AUTOSAR XML (schema 4-0-3)
package /CSCR_Code_pkg/CSCR_Code_swc
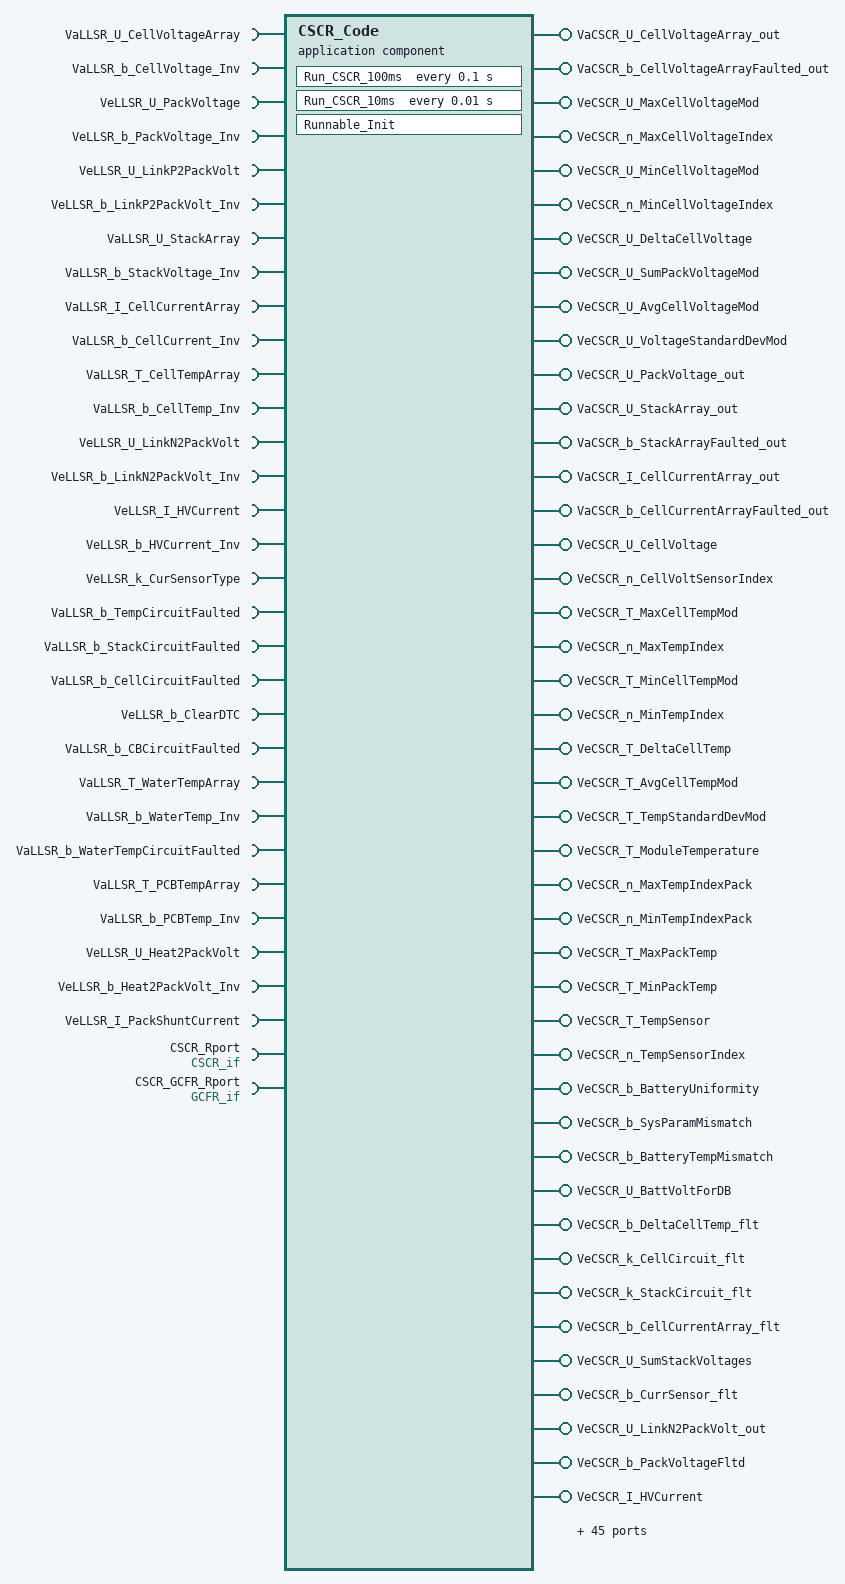
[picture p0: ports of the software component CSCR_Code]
  application sw component type CSCR_Code
    30 x require port:
      VaLLSR_U_CellVoltageArray: nonqueued-receiver-com-spec{data-element=VaLLSR_U_CellVoltageArray, init-value=96 x 0}, required-interface=VaLLSR_U_CellVoltageArray
      VaLLSR_b_CellVoltage_Inv: nonqueued-receiver-com-spec{data-element=VaLLSR_b_CellVoltage_Inv, init-value=96 x 0}, required-interface=VaLLSR_b_CellVoltage_Inv
      VeLLSR_U_PackVoltage: nonqueued-receiver-com-spec{data-element=VeLLSR_U_PackVoltage, init-value=0}, required-interface=VeLLSR_U_PackVoltage
      VeLLSR_b_PackVoltage_Inv: nonqueued-receiver-com-spec{data-element=VeLLSR_b_PackVoltage_Inv, init-value=0}, required-interface=VeLLSR_b_PackVoltage_Inv
      VeLLSR_U_LinkP2PackVolt: nonqueued-receiver-com-spec{data-element=VeLLSR_U_LinkP2PackVolt, init-value=0}, required-interface=VeLLSR_U_LinkP2PackVolt
      VeLLSR_b_LinkP2PackVolt_Inv: nonqueued-receiver-com-spec{data-element=VeLLSR_b_LinkP2PackVolt_Inv, init-value=0}, required-interface=VeLLSR_b_LinkP2PackVolt_Inv
      VaLLSR_U_StackArray: nonqueued-receiver-com-spec{data-element=VaLLSR_U_StackArray, init-value=8 x 0}, required-interface=VaLLSR_U_StackArray
      VaLLSR_b_StackVoltage_Inv: nonqueued-receiver-com-spec{data-element=VaLLSR_b_StackVoltage_Inv, init-value=8 x 0}, required-interface=VaLLSR_b_StackVoltage_Inv
      VaLLSR_I_CellCurrentArray: nonqueued-receiver-com-spec{data-element=VaLLSR_I_CellCurrentArray, init-value=[0, 0]}, required-interface=VaLLSR_I_CellCurrentArray
      VaLLSR_b_CellCurrent_Inv: nonqueued-receiver-com-spec{data-element=VaLLSR_b_CellCurrent_Inv, init-value=[0, 0]}, required-interface=VaLLSR_b_CellCurrent_Inv
      VaLLSR_T_CellTempArray: nonqueued-receiver-com-spec{data-element=VaLLSR_T_CellTempArray, init-value=16 x 0}, required-interface=VaLLSR_T_CellTempArray
      VaLLSR_b_CellTemp_Inv: nonqueued-receiver-com-spec{data-element=VaLLSR_b_CellTemp_Inv, init-value=16 x 0}, required-interface=VaLLSR_b_CellTemp_Inv
      VeLLSR_U_LinkN2PackVolt: nonqueued-receiver-com-spec{data-element=VeLLSR_U_LinkN2PackVolt, init-value=0}, required-interface=VeLLSR_U_LinkN2PackVolt
      VeLLSR_b_LinkN2PackVolt_Inv: nonqueued-receiver-com-spec{data-element=VeLLSR_b_LinkN2PackVolt_Inv, init-value=0}, required-interface=VeLLSR_b_LinkN2PackVolt_Inv
      VeLLSR_I_HVCurrent: nonqueued-receiver-com-spec{data-element=VeLLSR_I_HVCurrent, init-value=0}, required-interface=VeLLSR_I_HVCurrent
      VeLLSR_b_HVCurrent_Inv: nonqueued-receiver-com-spec{data-element=VeLLSR_b_HVCurrent_Inv, init-value=0}, required-interface=VeLLSR_b_HVCurrent_Inv
      VeLLSR_k_CurSensorType: nonqueued-receiver-com-spec{data-element=VeLLSR_k_CurSensorType, init-value=0}, required-interface=VeLLSR_k_CurSensorType
      VaLLSR_b_TempCircuitFaulted: nonqueued-receiver-com-spec{data-element=VaLLSR_b_TempCircuitFaulted, init-value=16 x 0}, required-interface=VaLLSR_b_TempCircuitFaulted
      VaLLSR_b_StackCircuitFaulted: nonqueued-receiver-com-spec{data-element=VaLLSR_b_StackCircuitFaulted, init-value=8 x 0}, required-interface=VaLLSR_b_StackCircuitFaulted
      VaLLSR_b_CellCircuitFaulted: nonqueued-receiver-com-spec{data-element=VaLLSR_b_CellCircuitFaulted, init-value=96 x 0}, required-interface=VaLLSR_b_CellCircuitFaulted
      VeLLSR_b_ClearDTC: nonqueued-receiver-com-spec{data-element=VeLLSR_b_ClearDTC, init-value=0}, required-interface=VeLLSR_b_ClearDTC
      VaLLSR_b_CBCircuitFaulted: nonqueued-receiver-com-spec{data-element=VaLLSR_b_CBCircuitFaulted, init-value=96 x 0}, required-interface=VaLLSR_b_CBCircuitFaulted
      VaLLSR_T_WaterTempArray: nonqueued-receiver-com-spec{data-element=VaLLSR_T_WaterTempArray, init-value=[0, 0]}, required-interface=VaLLSR_T_WaterTempArray
      VaLLSR_b_WaterTemp_Inv: nonqueued-receiver-com-spec{data-element=VaLLSR_b_WaterTemp_Inv, init-value=[0, 0]}, required-interface=VaLLSR_b_WaterTemp_Inv
      VaLLSR_b_WaterTempCircuitFaulted: nonqueued-receiver-com-spec{data-element=VaLLSR_b_WaterTempCircuitFaulted, init-value=[0, 0]}, required-interface=VaLLSR_b_WaterTempCircuitFaulted
      VaLLSR_T_PCBTempArray: nonqueued-receiver-com-spec{data-element=VaLLSR_T_PCBTempArray, init-value=11 x 0}, required-interface=VaLLSR_T_PCBTempArray
      VaLLSR_b_PCBTemp_Inv: nonqueued-receiver-com-spec{data-element=VaLLSR_b_PCBTemp_Inv, init-value=11 x 0}, required-interface=VaLLSR_b_PCBTemp_Inv
      VeLLSR_U_Heat2PackVolt: nonqueued-receiver-com-spec{data-element=VeLLSR_U_Heat2PackVolt, init-value=0}, required-interface=VeLLSR_U_Heat2PackVolt
      VeLLSR_b_Heat2PackVolt_Inv: nonqueued-receiver-com-spec{data-element=VeLLSR_b_Heat2PackVolt_Inv, init-value=0}, required-interface=VeLLSR_b_Heat2PackVolt_Inv
      VeLLSR_I_PackShuntCurrent: nonqueued-receiver-com-spec{data-element=VeLLSR_I_PackShuntCurrent, init-value=0}, required-interface=VeLLSR_I_PackShuntCurrent
    89 x provide port:
      VaCSCR_U_CellVoltageArray_out: nonqueued-sender-com-spec{data-element=VaCSCR_U_CellVoltageArray_out, init-value=96 x 0}, provided-interface=VaCSCR_U_CellVoltageArray_out
      VaCSCR_b_CellVoltageArrayFaulted_out: nonqueued-sender-com-spec{data-element=VaCSCR_b_CellVoltageArrayFaulted_out, init-value=96 x 0}, provided-interface=VaCSCR_b_CellVoltageArrayFaulted_out
      VeCSCR_U_MaxCellVoltageMod: nonqueued-sender-com-spec{data-element=VeCSCR_U_MaxCellVoltageMod, init-value=0}, provided-interface=VeCSCR_U_MaxCellVoltageMod
      VeCSCR_n_MaxCellVoltageIndex: nonqueued-sender-com-spec{data-element=VeCSCR_n_MaxCellVoltageIndex, init-value=0}, provided-interface=VeCSCR_n_MaxCellVoltageIndex
      VeCSCR_U_MinCellVoltageMod: nonqueued-sender-com-spec{data-element=VeCSCR_U_MinCellVoltageMod, init-value=0}, provided-interface=VeCSCR_U_MinCellVoltageMod
      VeCSCR_n_MinCellVoltageIndex: nonqueued-sender-com-spec{data-element=VeCSCR_n_MinCellVoltageIndex, init-value=0}, provided-interface=VeCSCR_n_MinCellVoltageIndex
      VeCSCR_U_DeltaCellVoltage: nonqueued-sender-com-spec{data-element=VeCSCR_U_DeltaCellVoltage, init-value=0}, provided-interface=VeCSCR_U_DeltaCellVoltage
      VeCSCR_U_SumPackVoltageMod: nonqueued-sender-com-spec{data-element=VeCSCR_U_SumPackVoltageMod, init-value=0}, provided-interface=VeCSCR_U_SumPackVoltageMod
      VeCSCR_U_AvgCellVoltageMod: nonqueued-sender-com-spec{data-element=VeCSCR_U_AvgCellVoltageMod, init-value=0}, provided-interface=VeCSCR_U_AvgCellVoltageMod
      VeCSCR_U_VoltageStandardDevMod: nonqueued-sender-com-spec{data-element=VeCSCR_U_VoltageStandardDevMod, init-value=0}, provided-interface=VeCSCR_U_VoltageStandardDevMod
      VeCSCR_U_PackVoltage_out: nonqueued-sender-com-spec{data-element=VeCSCR_U_PackVoltage_out, init-value=0}, provided-interface=VeCSCR_U_PackVoltage_out
      VaCSCR_U_StackArray_out: nonqueued-sender-com-spec{data-element=VaCSCR_U_StackArray_out, init-value=8 x 0}, provided-interface=VaCSCR_U_StackArray_out
      VaCSCR_b_StackArrayFaulted_out: nonqueued-sender-com-spec{data-element=VaCSCR_b_StackArrayFaulted_out, init-value=8 x 0}, provided-interface=VaCSCR_b_StackArrayFaulted_out
      VaCSCR_I_CellCurrentArray_out: nonqueued-sender-com-spec{data-element=VaCSCR_I_CellCurrentArray_out, init-value=[0, 0]}, provided-interface=VaCSCR_I_CellCurrentArray_out
      VaCSCR_b_CellCurrentArrayFaulted_out: nonqueued-sender-com-spec{data-element=VaCSCR_b_CellCurrentArrayFaulted_out, init-value=[0, 0]}, provided-interface=VaCSCR_b_CellCurrentArrayFaulted_out
      VeCSCR_U_CellVoltage: nonqueued-sender-com-spec{data-element=VeCSCR_U_CellVoltage, init-value=0}, provided-interface=VeCSCR_U_CellVoltage
      VeCSCR_n_CellVoltSensorIndex: nonqueued-sender-com-spec{data-element=VeCSCR_n_CellVoltSensorIndex, init-value=0}, provided-interface=VeCSCR_n_CellVoltSensorIndex
      VeCSCR_T_MaxCellTempMod: nonqueued-sender-com-spec{data-element=VeCSCR_T_MaxCellTempMod, init-value=0}, provided-interface=VeCSCR_T_MaxCellTempMod
      VeCSCR_n_MaxTempIndex: nonqueued-sender-com-spec{data-element=VeCSCR_n_MaxTempIndex, init-value=0}, provided-interface=VeCSCR_n_MaxTempIndex
      VeCSCR_T_MinCellTempMod: nonqueued-sender-com-spec{data-element=VeCSCR_T_MinCellTempMod, init-value=0}, provided-interface=VeCSCR_T_MinCellTempMod
      VeCSCR_n_MinTempIndex: nonqueued-sender-com-spec{data-element=VeCSCR_n_MinTempIndex, init-value=0}, provided-interface=VeCSCR_n_MinTempIndex
      VeCSCR_T_DeltaCellTemp: nonqueued-sender-com-spec{data-element=VeCSCR_T_DeltaCellTemp, init-value=0}, provided-interface=VeCSCR_T_DeltaCellTemp
      VeCSCR_T_AvgCellTempMod: nonqueued-sender-com-spec{data-element=VeCSCR_T_AvgCellTempMod, init-value=0}, provided-interface=VeCSCR_T_AvgCellTempMod
      VeCSCR_T_TempStandardDevMod: nonqueued-sender-com-spec{data-element=VeCSCR_T_TempStandardDevMod, init-value=0}, provided-interface=VeCSCR_T_TempStandardDevMod
      VeCSCR_T_ModuleTemperature: nonqueued-sender-com-spec{data-element=VeCSCR_T_ModuleTemperature, init-value=0}, provided-interface=VeCSCR_T_ModuleTemperature
      VeCSCR_n_MaxTempIndexPack: nonqueued-sender-com-spec{data-element=VeCSCR_n_MaxTempIndexPack, init-value=0}, provided-interface=VeCSCR_n_MaxTempIndexPack
      VeCSCR_n_MinTempIndexPack: nonqueued-sender-com-spec{data-element=VeCSCR_n_MinTempIndexPack, init-value=0}, provided-interface=VeCSCR_n_MinTempIndexPack
      VeCSCR_T_MaxPackTemp: nonqueued-sender-com-spec{data-element=VeCSCR_T_MaxPackTemp, init-value=0}, provided-interface=VeCSCR_T_MaxPackTemp
      VeCSCR_T_MinPackTemp: nonqueued-sender-com-spec{data-element=VeCSCR_T_MinPackTemp, init-value=0}, provided-interface=VeCSCR_T_MinPackTemp
      VeCSCR_T_TempSensor: nonqueued-sender-com-spec{data-element=VeCSCR_T_TempSensor, init-value=0}, provided-interface=VeCSCR_T_TempSensor
      VeCSCR_n_TempSensorIndex: nonqueued-sender-com-spec{data-element=VeCSCR_n_TempSensorIndex, init-value=0}, provided-interface=VeCSCR_n_TempSensorIndex
      VeCSCR_b_BatteryUniformity: nonqueued-sender-com-spec{data-element=VeCSCR_b_BatteryUniformity, init-value=0}, provided-interface=VeCSCR_b_BatteryUniformity
      VeCSCR_b_SysParamMismatch: nonqueued-sender-com-spec{data-element=VeCSCR_b_SysParamMismatch, init-value=0}, provided-interface=VeCSCR_b_SysParamMismatch
      VeCSCR_b_BatteryTempMismatch: nonqueued-sender-com-spec{data-element=VeCSCR_b_BatteryTempMismatch, init-value=0}, provided-interface=VeCSCR_b_BatteryTempMismatch
      VeCSCR_U_BattVoltForDB: nonqueued-sender-com-spec{data-element=VeCSCR_U_BattVoltForDB, init-value=0}, provided-interface=VeCSCR_U_BattVoltForDB
      VeCSCR_b_DeltaCellTemp_flt: nonqueued-sender-com-spec{data-element=VeCSCR_b_DeltaCellTemp_flt, init-value=0}, provided-interface=VeCSCR_b_DeltaCellTemp_flt
      VeCSCR_k_CellCircuit_flt: nonqueued-sender-com-spec{data-element=VeCSCR_k_CellCircuit_flt, init-value=0}, provided-interface=VeCSCR_k_CellCircuit_flt
      VeCSCR_k_StackCircuit_flt: nonqueued-sender-com-spec{data-element=VeCSCR_k_StackCircuit_flt, init-value=0}, provided-interface=VeCSCR_k_StackCircuit_flt
      VeCSCR_b_CellCurrentArray_flt: nonqueued-sender-com-spec{data-element=VeCSCR_b_CellCurrentArray_flt, init-value=0}, provided-interface=VeCSCR_b_CellCurrentArray_flt
      VeCSCR_U_SumStackVoltages: nonqueued-sender-com-spec{data-element=VeCSCR_U_SumStackVoltages, init-value=0}, provided-interface=VeCSCR_U_SumStackVoltages
      VeCSCR_b_CurrSensor_flt: nonqueued-sender-com-spec{data-element=VeCSCR_b_CurrSensor_flt, init-value=0}, provided-interface=VeCSCR_b_CurrSensor_flt
      VeCSCR_U_LinkN2PackVolt_out: nonqueued-sender-com-spec{data-element=VeCSCR_U_LinkN2PackVolt_out, init-value=0}, provided-interface=VeCSCR_U_LinkN2PackVolt_out
      VeCSCR_b_PackVoltageFltd: nonqueued-sender-com-spec{data-element=VeCSCR_b_PackVoltageFltd, init-value=0}, provided-interface=VeCSCR_b_PackVoltageFltd
      VeCSCR_I_HVCurrent: nonqueued-sender-com-spec{data-element=VeCSCR_I_HVCurrent, init-value=0}, provided-interface=VeCSCR_I_HVCurrent
      VeCSCR_b_HVCurrentFaulted: nonqueued-sender-com-spec{data-element=VeCSCR_b_HVCurrentFaulted, init-value=0}, provided-interface=VeCSCR_b_HVCurrentFaulted
      VeCSCR_k_CurSensorType: nonqueued-sender-com-spec{data-element=VeCSCR_k_CurSensorType, init-value=0}, provided-interface=VeCSCR_k_CurSensorType
      VeCSCR_b_CellUArrayReady: nonqueued-sender-com-spec{data-element=VeCSCR_b_CellUArrayReady, init-value=0}, provided-interface=VeCSCR_b_CellUArrayReady
      VeCSCR_k_CBCircuit_flt: nonqueued-sender-com-spec{data-element=VeCSCR_k_CBCircuit_flt, init-value=0}, provided-interface=VeCSCR_k_CBCircuit_flt
      VeCSCR_b_CellVoltage_Inv: nonqueued-sender-com-spec{data-element=VeCSCR_b_CellVoltage_Inv, init-value=0}, provided-interface=VeCSCR_b_CellVoltage_Inv
      VeCSCR_k_TempArray_flt: nonqueued-sender-com-spec{data-element=VeCSCR_k_TempArray_flt, init-value=0}, provided-interface=VeCSCR_k_TempArray_flt
      VeCSCR_b_QconOverTemp_L1_flt: nonqueued-sender-com-spec{data-element=VeCSCR_b_QconOverTemp_L1_flt, init-value=0}, provided-interface=VeCSCR_b_QconOverTemp_L1_flt
      VeCSCR_b_QconOverTemp_L2_flt: nonqueued-sender-com-spec{data-element=VeCSCR_b_QconOverTemp_L2_flt, init-value=0}, provided-interface=VeCSCR_b_QconOverTemp_L2_flt
      VeCSCR_b_CurrentSensor_flt: nonqueued-sender-com-spec{data-element=VeCSCR_b_CurrentSensor_flt, init-value=0}, provided-interface=VeCSCR_b_CurrentSensor_flt
      VeCSCR_T_MaxSenorTemp: nonqueued-sender-com-spec{data-element=VeCSCR_T_MaxSenorTemp, init-value=0}, provided-interface=VeCSCR_T_MaxSenorTemp
      VeCSCR_T_MinSenorTemp: nonqueued-sender-com-spec{data-element=VeCSCR_T_MinSenorTemp, init-value=0}, provided-interface=VeCSCR_T_MinSenorTemp
      VeCSCR_n_MaxSenorTempIndex: nonqueued-sender-com-spec{data-element=VeCSCR_n_MaxSenorTempIndex, init-value=0}, provided-interface=VeCSCR_n_MaxSenorTempIndex
      VeCSCR_n_MinSenorTempIndex: nonqueued-sender-com-spec{data-element=VeCSCR_n_MinSenorTempIndex, init-value=0}, provided-interface=VeCSCR_n_MinSenorTempIndex
      VaCSCR_T_CellTempArray_out: nonqueued-sender-com-spec{data-element=VaCSCR_T_CellTempArray_out, init-value=16 x 0}, provided-interface=VaCSCR_T_CellTempArray_out
      VeCSCR_k_TempArray_flt_CAN: nonqueued-sender-com-spec{data-element=VeCSCR_k_TempArray_flt_CAN, init-value=0}, provided-interface=VeCSCR_k_TempArray_flt_CAN
      VeCSCR_b_AveTempReady: nonqueued-sender-com-spec{data-element=VeCSCR_b_AveTempReady, init-value=0}, provided-interface=VeCSCR_b_AveTempReady
      VeCSCR_b_SafetyConnectStatus: nonqueued-sender-com-spec{data-element=VeCSCR_b_SafetyConnectStatus, init-value=0}, provided-interface=VeCSCR_b_SafetyConnectStatus
      VeCSCR_b_CellTemp_Inv: nonqueued-sender-com-spec{data-element=VeCSCR_b_CellTemp_Inv, init-value=0}, provided-interface=VeCSCR_b_CellTemp_Inv
      VaCSCR_dT_CellTempRate_out: nonqueued-sender-com-spec{data-element=VaCSCR_dT_CellTempRate_out, init-value=16 x 0}, provided-interface=VaCSCR_dT_CellTempRate_out
      VaCSCR_T_WaterTempArray: nonqueued-sender-com-spec{data-element=VaCSCR_T_WaterTempArray, init-value=[0, 0]}, provided-interface=VaCSCR_T_WaterTempArray
      VaCSCR_b_WaterTemp_Inv: nonqueued-sender-com-spec{data-element=VaCSCR_b_WaterTemp_Inv, init-value=[0, 0]}, provided-interface=VaCSCR_b_WaterTemp_Inv
      VeCSCR_k_WaterTemp_flt: nonqueued-sender-com-spec{data-element=VeCSCR_k_WaterTemp_flt, init-value=0}, provided-interface=VeCSCR_k_WaterTemp_flt
      VeCSCR_n_WaterTemp_flt_CAN: nonqueued-sender-com-spec{data-element=VeCSCR_n_WaterTemp_flt_CAN, init-value=0}, provided-interface=VeCSCR_n_WaterTemp_flt_CAN
      VeCSCR_T_MaxPCBTemp: nonqueued-sender-com-spec{data-element=VeCSCR_T_MaxPCBTemp, init-value=0}, provided-interface=VeCSCR_T_MaxPCBTemp
      VeCSCR_T_MinPCBTemp: nonqueued-sender-com-spec{data-element=VeCSCR_T_MinPCBTemp, init-value=0}, provided-interface=VeCSCR_T_MinPCBTemp
      VeCSCR_T_AvePCBTemp: nonqueued-sender-com-spec{data-element=VeCSCR_T_AvePCBTemp, init-value=0}, provided-interface=VeCSCR_T_AvePCBTemp
      VeCSCR_n_MaxPCBTempIndex: nonqueued-sender-com-spec{data-element=VeCSCR_n_MaxPCBTempIndex, init-value=0}, provided-interface=VeCSCR_n_MaxPCBTempIndex
      VeCSCR_n_MinPCBTempIndex: nonqueued-sender-com-spec{data-element=VeCSCR_n_MinPCBTempIndex, init-value=0}, provided-interface=VeCSCR_n_MinPCBTempIndex
      VeCSCR_b_PCBTemp_Inv: nonqueued-sender-com-spec{data-element=VeCSCR_b_PCBTemp_Inv, init-value=0}, provided-interface=VeCSCR_b_PCBTemp_Inv
      VeCSCR_U_Heat2PackVolt_out: nonqueued-sender-com-spec{data-element=VeCSCR_U_Heat2PackVolt_out, init-value=0}, provided-interface=VeCSCR_U_Heat2PackVolt_out
      VeCSCR_U_LinkP2PackVolt_out: nonqueued-sender-com-spec{data-element=VeCSCR_U_LinkP2PackVolt_out, init-value=0}, provided-interface=VeCSCR_U_LinkP2PackVolt_out
      VeCSCR_n_MaxVoltIndexPack: nonqueued-sender-com-spec{data-element=VeCSCR_n_MaxVoltIndexPack, init-value=0}, provided-interface=VeCSCR_n_MaxVoltIndexPack
      VeCSCR_n_MinVoltIndexPack: nonqueued-sender-com-spec{data-element=VeCSCR_n_MinVoltIndexPack, init-value=0}, provided-interface=VeCSCR_n_MinVoltIndexPack
      VeCSCR_U_LinkP2PackVolt_CAN: nonqueued-sender-com-spec{data-element=VeCSCR_U_LinkP2PackVolt_CAN, init-value=0}, provided-interface=VeCSCR_U_LinkP2PackVolt_CAN
      VeCSCR_U_LinkN2PackVolt_CAN: nonqueued-sender-com-spec{data-element=VeCSCR_U_LinkN2PackVolt_CAN, init-value=0}, provided-interface=VeCSCR_U_LinkN2PackVolt_CAN
      VeCSCR_U_Heat2PackVolt_CAN: nonqueued-sender-com-spec{data-element=VeCSCR_U_Heat2PackVolt_CAN, init-value=0}, provided-interface=VeCSCR_U_Heat2PackVolt_CAN
      VeCSCR_k_PCBTempInv_Flt: nonqueued-sender-com-spec{data-element=VeCSCR_k_PCBTempInv_Flt, init-value=0}, provided-interface=VeCSCR_k_PCBTempInv_Flt
      VeCSCR_k_PackVolt_flt: nonqueued-sender-com-spec{data-element=VeCSCR_k_PackVolt_flt, init-value=0}, provided-interface=VeCSCR_k_PackVolt_flt
      VeCSCR_k_LinkPVolt_flt: nonqueued-sender-com-spec{data-element=VeCSCR_k_LinkPVolt_flt, init-value=0}, provided-interface=VeCSCR_k_LinkPVolt_flt
      VeCSCR_k_LinkNVolt_flt: nonqueued-sender-com-spec{data-element=VeCSCR_k_LinkNVolt_flt, init-value=0}, provided-interface=VeCSCR_k_LinkNVolt_flt
      VeCSCR_k_HeatVolt_flt: nonqueued-sender-com-spec{data-element=VeCSCR_k_HeatVolt_flt, init-value=0}, provided-interface=VeCSCR_k_HeatVolt_flt
      VeCSCR_I_PackShuntCurrent: nonqueued-sender-com-spec{data-element=VeCSCR_I_PackShuntCurrent, init-value=0}, provided-interface=VeCSCR_I_PackShuntCurrent
      VeCSCR_b_PackShuntCurrentFaulted: nonqueued-sender-com-spec{data-element=VeCSCR_b_PackShuntCurrentFaulted, init-value=0}, provided-interface=VeCSCR_b_PackShuntCurrentFaulted
      VeCSCR_T_InletWaterTemp: nonqueued-sender-com-spec{data-element=VeCSCR_T_InletWaterTemp, init-value=0}, provided-interface=VeCSCR_T_InletWaterTemp
      VeCSCR_T_OutletWaterTemp: nonqueued-sender-com-spec{data-element=VeCSCR_T_OutletWaterTemp, init-value=0}, provided-interface=VeCSCR_T_OutletWaterTemp
    require port CSCR_Rport: required-interface=CSCR_if
    require port CSCR_GCFR_Rport: required-interface=GCFR_if
    behavior CSCR_Code: data-type-mapping=[CSCR_CodeDataTypeMappingsSet, WorkingDataTypeMappingsSet], handle-termination-and-restart=NO-SUPPORT
      timing event Event_Run_CSCR_100ms: start-on-event=Run_CSCR_100ms, period=0.1
      timing event Event_Run_CSCR_10ms: start-on-event=Run_CSCR_10ms, period=0.01
      runnable Runnable_Init: symbol=CSCR_Code_Init
        data-send-points:
          access OUT_VaCSCR_T_WaterTempArray_VaCSCR_T_WaterTempArray: accessed-variable=VaCSCR_T_WaterTempArray.VaCSCR_T_WaterTempArray
      runnable Run_CSCR_100ms
        data-read-access:
          9 x access:
            IN_VaLLSR_T_CellTempArray_VaLLSR_T_CellTempArray: accessed-variable=VaLLSR_T_CellTempArray.VaLLSR_T_CellTempArray
            IN_VaLLSR_T_PCBTempArray_VaLLSR_T_PCBTempArray: accessed-variable=VaLLSR_T_PCBTempArray.VaLLSR_T_PCBTempArray
            IN_VaLLSR_T_WaterTempArray_VaLLSR_T_WaterTempArray: accessed-variable=VaLLSR_T_WaterTempArray.VaLLSR_T_WaterTempArray
            IN_VaLLSR_b_CellTemp_Inv_VaLLSR_b_CellTemp_Inv: accessed-variable=VaLLSR_b_CellTemp_Inv.VaLLSR_b_CellTemp_Inv
            IN_VaLLSR_b_PCBTemp_Inv_VaLLSR_b_PCBTemp_Inv: accessed-variable=VaLLSR_b_PCBTemp_Inv.VaLLSR_b_PCBTemp_Inv
            IN_VaLLSR_b_TempCircuitFaulted_VaLLSR_b_TempCircuitFaulted: accessed-variable=VaLLSR_b_TempCircuitFaulted.VaLLSR_b_TempCircuitFaulted
            IN_VaLLSR_b_WaterTempCircuitFaulted_VaLLSR_b_49323721841c35e2: accessed-variable=VaLLSR_b_WaterTempCircuitFaulted.VaLLSR_b_WaterTempCircuitFaulted
            IN_VaLLSR_b_WaterTemp_Inv_VaLLSR_b_WaterTemp_Inv: accessed-variable=VaLLSR_b_WaterTemp_Inv.VaLLSR_b_WaterTemp_Inv
            IN_VeLLSR_b_ClearDTC_VeLLSR_b_ClearDTC: accessed-variable=VeLLSR_b_ClearDTC.VeLLSR_b_ClearDTC
        data-send-points:
          45 x access:
            OUT_VeCSCR_T_MaxCellTempMod_VeCSCR_T_MaxCellTempMod: accessed-variable=VeCSCR_T_MaxCellTempMod.VeCSCR_T_MaxCellTempMod
            OUT_VeCSCR_n_MaxTempIndex_VeCSCR_n_MaxTempIndex: accessed-variable=VeCSCR_n_MaxTempIndex.VeCSCR_n_MaxTempIndex
            OUT_VeCSCR_T_MinCellTempMod_VeCSCR_T_MinCellTempMod: accessed-variable=VeCSCR_T_MinCellTempMod.VeCSCR_T_MinCellTempMod
            OUT_VeCSCR_n_MinTempIndex_VeCSCR_n_MinTempIndex: accessed-variable=VeCSCR_n_MinTempIndex.VeCSCR_n_MinTempIndex
            OUT_VeCSCR_T_DeltaCellTemp_VeCSCR_T_DeltaCellTemp: accessed-variable=VeCSCR_T_DeltaCellTemp.VeCSCR_T_DeltaCellTemp
            OUT_VeCSCR_T_AvgCellTempMod_VeCSCR_T_AvgCellTempMod: accessed-variable=VeCSCR_T_AvgCellTempMod.VeCSCR_T_AvgCellTempMod
            OUT_VeCSCR_T_TempStandardDevMod_VeCSCR_T_TempStandardDevMod: accessed-variable=VeCSCR_T_TempStandardDevMod.VeCSCR_T_TempStandardDevMod
            OUT_VeCSCR_T_ModuleTemperature_VeCSCR_T_ModuleTemperature: accessed-variable=VeCSCR_T_ModuleTemperature.VeCSCR_T_ModuleTemperature
            OUT_VeCSCR_n_MaxTempIndexPack_VeCSCR_n_MaxTempIndexPack: accessed-variable=VeCSCR_n_MaxTempIndexPack.VeCSCR_n_MaxTempIndexPack
            OUT_VeCSCR_n_MinTempIndexPack_VeCSCR_n_MinTempIndexPack: accessed-variable=VeCSCR_n_MinTempIndexPack.VeCSCR_n_MinTempIndexPack
            OUT_VeCSCR_T_MaxPackTemp_VeCSCR_T_MaxPackTemp: accessed-variable=VeCSCR_T_MaxPackTemp.VeCSCR_T_MaxPackTemp
            OUT_VeCSCR_T_MinPackTemp_VeCSCR_T_MinPackTemp: accessed-variable=VeCSCR_T_MinPackTemp.VeCSCR_T_MinPackTemp
            OUT_VeCSCR_T_TempSensor_VeCSCR_T_TempSensor: accessed-variable=VeCSCR_T_TempSensor.VeCSCR_T_TempSensor
            OUT_VeCSCR_n_TempSensorIndex_VeCSCR_n_TempSensorIndex: accessed-variable=VeCSCR_n_TempSensorIndex.VeCSCR_n_TempSensorIndex
            OUT_VeCSCR_b_BatteryUniformity_VeCSCR_b_BatteryUniformity: accessed-variable=VeCSCR_b_BatteryUniformity.VeCSCR_b_BatteryUniformity
            OUT_VeCSCR_b_SysParamMismatch_VeCSCR_b_SysParamMismatch: accessed-variable=VeCSCR_b_SysParamMismatch.VeCSCR_b_SysParamMismatch
            OUT_VeCSCR_b_BatteryTempMismatch_VeCSCR_b_BatteryTempMismatch: accessed-variable=VeCSCR_b_BatteryTempMismatch.VeCSCR_b_BatteryTempMismatch
            OUT_VeCSCR_b_DeltaCellTemp_flt_VeCSCR_b_DeltaCellTemp_flt: accessed-variable=VeCSCR_b_DeltaCellTemp_flt.VeCSCR_b_DeltaCellTemp_flt
            OUT_VeCSCR_k_TempArray_flt_VeCSCR_k_TempArray_flt: accessed-variable=VeCSCR_k_TempArray_flt.VeCSCR_k_TempArray_flt
            OUT_VeCSCR_b_QconOverTemp_L1_flt_VeCSCR_b_QconOverTemp_L1_flt: accessed-variable=VeCSCR_b_QconOverTemp_L1_flt.VeCSCR_b_QconOverTemp_L1_flt
            OUT_VeCSCR_b_QconOverTemp_L2_flt_VeCSCR_b_QconOverTemp_L2_flt: accessed-variable=VeCSCR_b_QconOverTemp_L2_flt.VeCSCR_b_QconOverTemp_L2_flt
            OUT_VeCSCR_b_CurrentSensor_flt_VeCSCR_b_CurrentSensor_flt: accessed-variable=VeCSCR_b_CurrentSensor_flt.VeCSCR_b_CurrentSensor_flt
            OUT_VeCSCR_T_MaxSenorTemp_VeCSCR_T_MaxSenorTemp: accessed-variable=VeCSCR_T_MaxSenorTemp.VeCSCR_T_MaxSenorTemp
            OUT_VeCSCR_T_MinSenorTemp_VeCSCR_T_MinSenorTemp: accessed-variable=VeCSCR_T_MinSenorTemp.VeCSCR_T_MinSenorTemp
            OUT_VeCSCR_n_MaxSenorTempIndex_VeCSCR_n_MaxSenorTempIndex: accessed-variable=VeCSCR_n_MaxSenorTempIndex.VeCSCR_n_MaxSenorTempIndex
            OUT_VeCSCR_n_MinSenorTempIndex_VeCSCR_n_MinSenorTempIndex: accessed-variable=VeCSCR_n_MinSenorTempIndex.VeCSCR_n_MinSenorTempIndex
            OUT_VaCSCR_T_CellTempArray_out_VaCSCR_T_CellTempArray_out: accessed-variable=VaCSCR_T_CellTempArray_out.VaCSCR_T_CellTempArray_out
            OUT_VeCSCR_k_TempArray_flt_CAN_VeCSCR_k_TempArray_flt_CAN: accessed-variable=VeCSCR_k_TempArray_flt_CAN.VeCSCR_k_TempArray_flt_CAN
            OUT_VeCSCR_b_AveTempReady_VeCSCR_b_AveTempReady: accessed-variable=VeCSCR_b_AveTempReady.VeCSCR_b_AveTempReady
            OUT_VeCSCR_b_SafetyConnectStatus_VeCSCR_b_SafetyConnectStatus: accessed-variable=VeCSCR_b_SafetyConnectStatus.VeCSCR_b_SafetyConnectStatus
            OUT_VeCSCR_b_CellTemp_Inv_VeCSCR_b_CellTemp_Inv: accessed-variable=VeCSCR_b_CellTemp_Inv.VeCSCR_b_CellTemp_Inv
            OUT_VaCSCR_dT_CellTempRate_out_VaCSCR_dT_CellTempRate_out: accessed-variable=VaCSCR_dT_CellTempRate_out.VaCSCR_dT_CellTempRate_out
            OUT_VaCSCR_T_WaterTempArray_VaCSCR_T_WaterTempArray: accessed-variable=VaCSCR_T_WaterTempArray.VaCSCR_T_WaterTempArray
            OUT_VaCSCR_b_WaterTemp_Inv_VaCSCR_b_WaterTemp_Inv: accessed-variable=VaCSCR_b_WaterTemp_Inv.VaCSCR_b_WaterTemp_Inv
            OUT_VeCSCR_k_WaterTemp_flt_VeCSCR_k_WaterTemp_flt: accessed-variable=VeCSCR_k_WaterTemp_flt.VeCSCR_k_WaterTemp_flt
            OUT_VeCSCR_n_WaterTemp_flt_CAN_VeCSCR_n_WaterTemp_flt_CAN: accessed-variable=VeCSCR_n_WaterTemp_flt_CAN.VeCSCR_n_WaterTemp_flt_CAN
            OUT_VeCSCR_T_MaxPCBTemp_VeCSCR_T_MaxPCBTemp: accessed-variable=VeCSCR_T_MaxPCBTemp.VeCSCR_T_MaxPCBTemp
            OUT_VeCSCR_T_MinPCBTemp_VeCSCR_T_MinPCBTemp: accessed-variable=VeCSCR_T_MinPCBTemp.VeCSCR_T_MinPCBTemp
            OUT_VeCSCR_T_AvePCBTemp_VeCSCR_T_AvePCBTemp: accessed-variable=VeCSCR_T_AvePCBTemp.VeCSCR_T_AvePCBTemp
            OUT_VeCSCR_n_MaxPCBTempIndex_VeCSCR_n_MaxPCBTempIndex: accessed-variable=VeCSCR_n_MaxPCBTempIndex.VeCSCR_n_MaxPCBTempIndex
            OUT_VeCSCR_n_MinPCBTempIndex_VeCSCR_n_MinPCBTempIndex: accessed-variable=VeCSCR_n_MinPCBTempIndex.VeCSCR_n_MinPCBTempIndex
            OUT_VeCSCR_b_PCBTemp_Inv_VeCSCR_b_PCBTemp_Inv: accessed-variable=VeCSCR_b_PCBTemp_Inv.VeCSCR_b_PCBTemp_Inv
            OUT_VeCSCR_k_PCBTempInv_Flt_VeCSCR_k_PCBTempInv_Flt: accessed-variable=VeCSCR_k_PCBTempInv_Flt.VeCSCR_k_PCBTempInv_Flt
            OUT_VeCSCR_T_InletWaterTemp_VeCSCR_T_InletWaterTemp: accessed-variable=VeCSCR_T_InletWaterTemp.VeCSCR_T_InletWaterTemp
            OUT_VeCSCR_T_OutletWaterTemp_VeCSCR_T_OutletWaterTemp: accessed-variable=VeCSCR_T_OutletWaterTemp.VeCSCR_T_OutletWaterTemp
        107 x parameter access:
          CALPRM_CSCR_Rport_KaCSCR_T_OvrdCellTempArrayVals: accessed-parameter=CSCR_Rport.KaCSCR_T_OvrdCellTempArrayVals
          CALPRM_CSCR_Rport_KaCSCR_b_OvrdCellTempFltArrayVals: accessed-parameter=CSCR_Rport.KaCSCR_b_OvrdCellTempFltArrayVals
          CALPRM_CSCR_Rport_KaCSCR_b_WaterTemp_Inv_En: accessed-parameter=CSCR_Rport.KaCSCR_b_WaterTemp_Inv_En
          CALPRM_CSCR_Rport_KaCSCR_b_WaterTemp_Inv_Val: accessed-parameter=CSCR_Rport.KaCSCR_b_WaterTemp_Inv_Val
          CALPRM_CSCR_Rport_KaCSCR_dT_CellTempRate_out_Val: accessed-parameter=CSCR_Rport.KaCSCR_dT_CellTempRate_out_Val
          CALPRM_CSCR_Rport_KaLLSR_b_TempCircuitFaulted_Val: accessed-parameter=CSCR_Rport.KaLLSR_b_TempCircuitFaulted_Val
          CALPRM_CSCR_Rport_KaLLSR_b_WaterTempCircuitFaulted_Val: accessed-parameter=CSCR_Rport.KaLLSR_b_WaterTempCircuitFaulted_Val
          CALPRM_CSCR_Rport_KeCSCR_Cnt_DeltaCellTempFltDbnc: accessed-parameter=CSCR_Rport.KeCSCR_Cnt_DeltaCellTempFltDbnc
          CALPRM_CSCR_Rport_KeCSCR_Cnt_NumPcbTempSens: accessed-parameter=CSCR_Rport.KeCSCR_Cnt_NumPcbTempSens
          CALPRM_CSCR_Rport_KeCSCR_Cnt_ThermistorCountSingle: accessed-parameter=CSCR_Rport.KeCSCR_Cnt_ThermistorCountSingle
          CALPRM_CSCR_Rport_KeCSCR_T_AvePCBTemp_Val: accessed-parameter=CSCR_Rport.KeCSCR_T_AvePCBTemp_Val
          CALPRM_CSCR_Rport_KeCSCR_T_AvgCellTempMod_maxVal: accessed-parameter=CSCR_Rport.KeCSCR_T_AvgCellTempMod_maxVal
          CALPRM_CSCR_Rport_KeCSCR_T_AvgCellTempMod_minVal: accessed-parameter=CSCR_Rport.KeCSCR_T_AvgCellTempMod_minVal
          CALPRM_CSCR_Rport_KeCSCR_T_CellTempArray_out_maxVal: accessed-parameter=CSCR_Rport.KeCSCR_T_CellTempArray_out_maxVal
          CALPRM_CSCR_Rport_KeCSCR_T_CellTempArray_out_minVal: accessed-parameter=CSCR_Rport.KeCSCR_T_CellTempArray_out_minVal
          CALPRM_CSCR_Rport_KeCSCR_T_DeltaCellTemp_Val: accessed-parameter=CSCR_Rport.KeCSCR_T_DeltaCellTemp_Val
          CALPRM_CSCR_Rport_KeCSCR_T_DeltaCellTemp_maxVal: accessed-parameter=CSCR_Rport.KeCSCR_T_DeltaCellTemp_maxVal
          CALPRM_CSCR_Rport_KeCSCR_T_DeltaCellTemp_minVal: accessed-parameter=CSCR_Rport.KeCSCR_T_DeltaCellTemp_minVal
          CALPRM_CSCR_Rport_KeCSCR_T_MaxCellTempMod_maxVal: accessed-parameter=CSCR_Rport.KeCSCR_T_MaxCellTempMod_maxVal
          CALPRM_CSCR_Rport_KeCSCR_T_MaxCellTempMod_minVal: accessed-parameter=CSCR_Rport.KeCSCR_T_MaxCellTempMod_minVal
          CALPRM_CSCR_Rport_KeCSCR_T_MaxCellTempOvrdVal: accessed-parameter=CSCR_Rport.KeCSCR_T_MaxCellTempOvrdVal
          CALPRM_CSCR_Rport_KeCSCR_T_MaxPCBTemp_Val: accessed-parameter=CSCR_Rport.KeCSCR_T_MaxPCBTemp_Val
          CALPRM_CSCR_Rport_KeCSCR_T_MaxPackTempOvrdVal: accessed-parameter=CSCR_Rport.KeCSCR_T_MaxPackTempOvrdVal
          CALPRM_CSCR_Rport_KeCSCR_T_MaxPackTemp_maxVal: accessed-parameter=CSCR_Rport.KeCSCR_T_MaxPackTemp_maxVal
          CALPRM_CSCR_Rport_KeCSCR_T_MaxPackTemp_minVal: accessed-parameter=CSCR_Rport.KeCSCR_T_MaxPackTemp_minVal
          CALPRM_CSCR_Rport_KeCSCR_T_MaxSenorTempIndexOvrdVal: accessed-parameter=CSCR_Rport.KeCSCR_T_MaxSenorTempIndexOvrdVal
          CALPRM_CSCR_Rport_KeCSCR_T_MaxSenorTempOvrdVal: accessed-parameter=CSCR_Rport.KeCSCR_T_MaxSenorTempOvrdVal
          CALPRM_CSCR_Rport_KeCSCR_T_MaxTempFault: accessed-parameter=CSCR_Rport.KeCSCR_T_MaxTempFault
          CALPRM_CSCR_Rport_KeCSCR_T_MinCellTempMod_maxVal: accessed-parameter=CSCR_Rport.KeCSCR_T_MinCellTempMod_maxVal
          CALPRM_CSCR_Rport_KeCSCR_T_MinCellTempMod_minVal: accessed-parameter=CSCR_Rport.KeCSCR_T_MinCellTempMod_minVal
          CALPRM_CSCR_Rport_KeCSCR_T_MinCellTempOvrdVal: accessed-parameter=CSCR_Rport.KeCSCR_T_MinCellTempOvrdVal
          CALPRM_CSCR_Rport_KeCSCR_T_MinPCBTemp_Val: accessed-parameter=CSCR_Rport.KeCSCR_T_MinPCBTemp_Val
          CALPRM_CSCR_Rport_KeCSCR_T_MinPackTempOvrdVal: accessed-parameter=CSCR_Rport.KeCSCR_T_MinPackTempOvrdVal
          CALPRM_CSCR_Rport_KeCSCR_T_MinPackTemp_maxVal: accessed-parameter=CSCR_Rport.KeCSCR_T_MinPackTemp_maxVal
          CALPRM_CSCR_Rport_KeCSCR_T_MinPackTemp_minVal: accessed-parameter=CSCR_Rport.KeCSCR_T_MinPackTemp_minVal
          CALPRM_CSCR_Rport_KeCSCR_T_MinSenorTempIndexOvrdVal: accessed-parameter=CSCR_Rport.KeCSCR_T_MinSenorTempIndexOvrdVal
          CALPRM_CSCR_Rport_KeCSCR_T_MinSenorTempOvrdVal: accessed-parameter=CSCR_Rport.KeCSCR_T_MinSenorTempOvrdVal
          CALPRM_CSCR_Rport_KeCSCR_T_MinTempFault: accessed-parameter=CSCR_Rport.KeCSCR_T_MinTempFault
          CALPRM_CSCR_Rport_KeCSCR_T_ModuleTemperatureOvrdVal: accessed-parameter=CSCR_Rport.KeCSCR_T_ModuleTemperatureOvrdVal
          CALPRM_CSCR_Rport_KeCSCR_T_OvrdAvgCellTempVal: accessed-parameter=CSCR_Rport.KeCSCR_T_OvrdAvgCellTempVal
          CALPRM_CSCR_Rport_KeCSCR_T_PCBTempDeftVal: accessed-parameter=CSCR_Rport.KeCSCR_T_PCBTempDeftVal
          CALPRM_CSCR_Rport_KeCSCR_T_WaterTempDeftVal: accessed-parameter=CSCR_Rport.KeCSCR_T_WaterTempDeftVal
          CALPRM_CSCR_Rport_KeCSCR_U_PackTempDefaultVal: accessed-parameter=CSCR_Rport.KeCSCR_U_PackTempDefaultVal
          CALPRM_CSCR_Rport_KeCSCR_b_AvePCBTemp_En: accessed-parameter=CSCR_Rport.KeCSCR_b_AvePCBTemp_En
          CALPRM_CSCR_Rport_KeCSCR_b_BatteryTempMismatchOvrd: accessed-parameter=CSCR_Rport.KeCSCR_b_BatteryTempMismatchOvrd
          CALPRM_CSCR_Rport_KeCSCR_b_BatteryTempMismatchOvrdVal: accessed-parameter=CSCR_Rport.KeCSCR_b_BatteryTempMismatchOvrdVal
          CALPRM_CSCR_Rport_KeCSCR_b_BatteryUniformityOvrd: accessed-parameter=CSCR_Rport.KeCSCR_b_BatteryUniformityOvrd
          CALPRM_CSCR_Rport_KeCSCR_b_BatteryUniformityOvrdVal: accessed-parameter=CSCR_Rport.KeCSCR_b_BatteryUniformityOvrdVal
          CALPRM_CSCR_Rport_KeCSCR_b_CellTempLPFEnable: accessed-parameter=CSCR_Rport.KeCSCR_b_CellTempLPFEnable
          CALPRM_CSCR_Rport_KeCSCR_b_CellTempRate_out_En: accessed-parameter=CSCR_Rport.KeCSCR_b_CellTempRate_out_En
          CALPRM_CSCR_Rport_KeCSCR_b_CellTemp_Inv_En: accessed-parameter=CSCR_Rport.KeCSCR_b_CellTemp_Inv_En
          CALPRM_CSCR_Rport_KeCSCR_b_CellTemp_Inv_Val: accessed-parameter=CSCR_Rport.KeCSCR_b_CellTemp_Inv_Val
          CALPRM_CSCR_Rport_KeCSCR_b_CurrentSensorFltOvrd: accessed-parameter=CSCR_Rport.KeCSCR_b_CurrentSensorFltOvrd
          CALPRM_CSCR_Rport_KeCSCR_b_CurrentSensorFltOvrdVal: accessed-parameter=CSCR_Rport.KeCSCR_b_CurrentSensorFltOvrdVal
          CALPRM_CSCR_Rport_KeCSCR_b_DeltaCellTempFltOvrd: accessed-parameter=CSCR_Rport.KeCSCR_b_DeltaCellTempFltOvrd
          CALPRM_CSCR_Rport_KeCSCR_b_DeltaCellTempFltOvrdVal: accessed-parameter=CSCR_Rport.KeCSCR_b_DeltaCellTempFltOvrdVal
          CALPRM_CSCR_Rport_KeCSCR_b_DeltaCellTemp_En: accessed-parameter=CSCR_Rport.KeCSCR_b_DeltaCellTemp_En
          CALPRM_CSCR_Rport_KeCSCR_b_FaultValFilterEn: accessed-parameter=CSCR_Rport.KeCSCR_b_FaultValFilterEn
          CALPRM_CSCR_Rport_KeCSCR_b_MaxCellTempIndexOvrd: accessed-parameter=CSCR_Rport.KeCSCR_b_MaxCellTempIndexOvrd
          CALPRM_CSCR_Rport_KeCSCR_b_MaxPCBTempIndex_En: accessed-parameter=CSCR_Rport.KeCSCR_b_MaxPCBTempIndex_En
          CALPRM_CSCR_Rport_KeCSCR_b_MaxPCBTemp_En: accessed-parameter=CSCR_Rport.KeCSCR_b_MaxPCBTemp_En
          CALPRM_CSCR_Rport_KeCSCR_b_MaxPackTempOvrd: accessed-parameter=CSCR_Rport.KeCSCR_b_MaxPackTempOvrd
          CALPRM_CSCR_Rport_KeCSCR_b_MaxSenorTempIndexOvrd: accessed-parameter=CSCR_Rport.KeCSCR_b_MaxSenorTempIndexOvrd
          CALPRM_CSCR_Rport_KeCSCR_b_MaxSenorTempOvrd: accessed-parameter=CSCR_Rport.KeCSCR_b_MaxSenorTempOvrd
          CALPRM_CSCR_Rport_KeCSCR_b_MaxTempIndexPackOvrd: accessed-parameter=CSCR_Rport.KeCSCR_b_MaxTempIndexPackOvrd
          CALPRM_CSCR_Rport_KeCSCR_b_MinCellTempIndexOvrd: accessed-parameter=CSCR_Rport.KeCSCR_b_MinCellTempIndexOvrd
          CALPRM_CSCR_Rport_KeCSCR_b_MinPCBTempIndex_En: accessed-parameter=CSCR_Rport.KeCSCR_b_MinPCBTempIndex_En
          CALPRM_CSCR_Rport_KeCSCR_b_MinPCBTemp_En: accessed-parameter=CSCR_Rport.KeCSCR_b_MinPCBTemp_En
          CALPRM_CSCR_Rport_KeCSCR_b_MinPackTempOvrd: accessed-parameter=CSCR_Rport.KeCSCR_b_MinPackTempOvrd
          CALPRM_CSCR_Rport_KeCSCR_b_MinSenorTempIndexOvrd: accessed-parameter=CSCR_Rport.KeCSCR_b_MinSenorTempIndexOvrd
          CALPRM_CSCR_Rport_KeCSCR_b_MinSenorTempOvrd: accessed-parameter=CSCR_Rport.KeCSCR_b_MinSenorTempOvrd
          CALPRM_CSCR_Rport_KeCSCR_b_MinTempIndexPackOvrd: accessed-parameter=CSCR_Rport.KeCSCR_b_MinTempIndexPackOvrd
          CALPRM_CSCR_Rport_KeCSCR_b_ModuleTemperatureOvrd: accessed-parameter=CSCR_Rport.KeCSCR_b_ModuleTemperatureOvrd
          CALPRM_CSCR_Rport_KeCSCR_b_OvrdAvgCellTemp: accessed-parameter=CSCR_Rport.KeCSCR_b_OvrdAvgCellTemp
          CALPRM_CSCR_Rport_KeCSCR_b_OvrdMaxCellTemp: accessed-parameter=CSCR_Rport.KeCSCR_b_OvrdMaxCellTemp
          CALPRM_CSCR_Rport_KeCSCR_b_OvrdMinCellTemp: accessed-parameter=CSCR_Rport.KeCSCR_b_OvrdMinCellTemp
          CALPRM_CSCR_Rport_KeCSCR_b_OvrdTempArray: accessed-parameter=CSCR_Rport.KeCSCR_b_OvrdTempArray
          CALPRM_CSCR_Rport_KeCSCR_b_OvrdTempFltArray: accessed-parameter=CSCR_Rport.KeCSCR_b_OvrdTempFltArray
          CALPRM_CSCR_Rport_KeCSCR_b_PCBTempLPFEnable: accessed-parameter=CSCR_Rport.KeCSCR_b_PCBTempLPFEnable
          CALPRM_CSCR_Rport_KeCSCR_b_PCBTemp_Inv_En: accessed-parameter=CSCR_Rport.KeCSCR_b_PCBTemp_Inv_En
          CALPRM_CSCR_Rport_KeCSCR_b_PCBTemp_Inv_Val: accessed-parameter=CSCR_Rport.KeCSCR_b_PCBTemp_Inv_Val
          CALPRM_CSCR_Rport_KeCSCR_b_SafetyConnectStatus_En: accessed-parameter=CSCR_Rport.KeCSCR_b_SafetyConnectStatus_En
          CALPRM_CSCR_Rport_KeCSCR_b_SafetyConnectStatus_Val: accessed-parameter=CSCR_Rport.KeCSCR_b_SafetyConnectStatus_Val
          CALPRM_CSCR_Rport_KeCSCR_b_SysParamMismatchOvrd: accessed-parameter=CSCR_Rport.KeCSCR_b_SysParamMismatchOvrd
          CALPRM_CSCR_Rport_KeCSCR_b_SysParamMismatchOvrdVal: accessed-parameter=CSCR_Rport.KeCSCR_b_SysParamMismatchOvrdVal
          CALPRM_CSCR_Rport_KeCSCR_b_TempArray_flt_CAN_En: accessed-parameter=CSCR_Rport.KeCSCR_b_TempArray_flt_CAN_En
          CALPRM_CSCR_Rport_KeCSCR_b_TempArray_flt_En: accessed-parameter=CSCR_Rport.KeCSCR_b_TempArray_flt_En
          CALPRM_CSCR_Rport_KeCSCR_b_WaterTempLPFEnable: accessed-parameter=CSCR_Rport.KeCSCR_b_WaterTempLPFEnable
          CALPRM_CSCR_Rport_KeCSCR_k_TempArray_flt_CAN_Val: accessed-parameter=CSCR_Rport.KeCSCR_k_TempArray_flt_CAN_Val
          CALPRM_CSCR_Rport_KeCSCR_k_TempArray_flt_Val: accessed-parameter=CSCR_Rport.KeCSCR_k_TempArray_flt_Val
          CALPRM_CSCR_Rport_KeCSCR_n_MaxCellTempIndexOvrdVal: accessed-parameter=CSCR_Rport.KeCSCR_n_MaxCellTempIndexOvrdVal
          CALPRM_CSCR_Rport_KeCSCR_n_MaxPCBTempIndex_Val: accessed-parameter=CSCR_Rport.KeCSCR_n_MaxPCBTempIndex_Val
          CALPRM_CSCR_Rport_KeCSCR_n_MaxTempIndexPackOvrdVal: accessed-parameter=CSCR_Rport.KeCSCR_n_MaxTempIndexPackOvrdVal
          CALPRM_CSCR_Rport_KeCSCR_n_MinCellTempIndexOvrdVal: accessed-parameter=CSCR_Rport.KeCSCR_n_MinCellTempIndexOvrdVal
          CALPRM_CSCR_Rport_KeCSCR_n_MinPCBTempIndex_Val: accessed-parameter=CSCR_Rport.KeCSCR_n_MinPCBTempIndex_Val
          CALPRM_CSCR_Rport_KeCSCR_n_MinTempIndexPackOvrdVal: accessed-parameter=CSCR_Rport.KeCSCR_n_MinTempIndexPackOvrdVal
          CALPRM_CSCR_Rport_KeCSCR_r_TempLPFGain: accessed-parameter=CSCR_Rport.KeCSCR_r_TempLPFGain
          CALPRM_CSCR_Rport_KeCSCR_t_CellTempRateTimeConstant: accessed-parameter=CSCR_Rport.KeCSCR_t_CellTempRateTimeConstant
          CALPRM_CSCR_Rport_KeCSCR_t_SlowSampleRate: accessed-parameter=CSCR_Rport.KeCSCR_t_SlowSampleRate
          CALPRM_CSCR_Rport_KeCSCR_t_TempCircuitFaultDeMaturation: accessed-parameter=CSCR_Rport.KeCSCR_t_TempCircuitFaultDeMaturation
          CALPRM_CSCR_Rport_KeCSCR_t_TempCircuitFaultMaturation: accessed-parameter=CSCR_Rport.KeCSCR_t_TempCircuitFaultMaturation
          CALPRM_CSCR_Rport_KeCSCR_t_TempFncCall: accessed-parameter=CSCR_Rport.KeCSCR_t_TempFncCall
          CALPRM_CSCR_Rport_KeCSCR_t_TempLPFWarmupTime: accessed-parameter=CSCR_Rport.KeCSCR_t_TempLPFWarmupTime
          CALPRM_CSCR_GCFR_Rport_KeGCFR_Cnt_NumberOfWaterThermistors: accessed-parameter=CSCR_GCFR_Rport.KeGCFR_Cnt_NumberOfWaterThermistors
          CALPRM_CSCR_GCFR_Rport_KeGCFR_Cnt_NumberofTempReadings: accessed-parameter=CSCR_GCFR_Rport.KeGCFR_Cnt_NumberofTempReadings
          CALPRM_CSCR_Rport_KeLLSR_b_TempCircuitFaulted_En: accessed-parameter=CSCR_Rport.KeLLSR_b_TempCircuitFaulted_En
          CALPRM_CSCR_Rport_KeLLSR_b_WaterTempCircuitFaulted_En: accessed-parameter=CSCR_Rport.KeLLSR_b_WaterTempCircuitFaulted_En
      runnable Run_CSCR_10ms
        data-read-access:
          22 x access:
            IN_VaLLSR_I_CellCurrentArray_VaLLSR_I_CellCurrentArray: accessed-variable=VaLLSR_I_CellCurrentArray.VaLLSR_I_CellCurrentArray
            IN_VaLLSR_U_CellVoltageArray_VaLLSR_U_CellVoltageArray: accessed-variable=VaLLSR_U_CellVoltageArray.VaLLSR_U_CellVoltageArray
            IN_VaLLSR_U_StackArray_VaLLSR_U_StackArray: accessed-variable=VaLLSR_U_StackArray.VaLLSR_U_StackArray
            IN_VaLLSR_b_CBCircuitFaulted_VaLLSR_b_CBCircuitFaulted: accessed-variable=VaLLSR_b_CBCircuitFaulted.VaLLSR_b_CBCircuitFaulted
            IN_VaLLSR_b_CellCircuitFaulted_VaLLSR_b_CellCircuitFaulted: accessed-variable=VaLLSR_b_CellCircuitFaulted.VaLLSR_b_CellCircuitFaulted
            IN_VaLLSR_b_CellCurrent_Inv_VaLLSR_b_CellCurrent_Inv: accessed-variable=VaLLSR_b_CellCurrent_Inv.VaLLSR_b_CellCurrent_Inv
            IN_VaLLSR_b_CellVoltage_Inv_VaLLSR_b_CellVoltage_Inv: accessed-variable=VaLLSR_b_CellVoltage_Inv.VaLLSR_b_CellVoltage_Inv
            IN_VaLLSR_b_StackCircuitFaulted_VaLLSR_b_StackCircuitFaulted: accessed-variable=VaLLSR_b_StackCircuitFaulted.VaLLSR_b_StackCircuitFaulted
            IN_VaLLSR_b_StackVoltage_Inv_VaLLSR_b_StackVoltage_Inv: accessed-variable=VaLLSR_b_StackVoltage_Inv.VaLLSR_b_StackVoltage_Inv
            IN_VeLLSR_I_HVCurrent_VeLLSR_I_HVCurrent: accessed-variable=VeLLSR_I_HVCurrent.VeLLSR_I_HVCurrent
            IN_VeLLSR_I_PackShuntCurrent_VeLLSR_I_PackShuntCurrent: accessed-variable=VeLLSR_I_PackShuntCurrent.VeLLSR_I_PackShuntCurrent
            IN_VeLLSR_U_Heat2PackVolt_VeLLSR_U_Heat2PackVolt: accessed-variable=VeLLSR_U_Heat2PackVolt.VeLLSR_U_Heat2PackVolt
            IN_VeLLSR_U_LinkN2PackVolt_VeLLSR_U_LinkN2PackVolt: accessed-variable=VeLLSR_U_LinkN2PackVolt.VeLLSR_U_LinkN2PackVolt
            IN_VeLLSR_U_LinkP2PackVolt_VeLLSR_U_LinkP2PackVolt: accessed-variable=VeLLSR_U_LinkP2PackVolt.VeLLSR_U_LinkP2PackVolt
            IN_VeLLSR_U_PackVoltage_VeLLSR_U_PackVoltage: accessed-variable=VeLLSR_U_PackVoltage.VeLLSR_U_PackVoltage
            IN_VeLLSR_b_ClearDTC_VeLLSR_b_ClearDTC: accessed-variable=VeLLSR_b_ClearDTC.VeLLSR_b_ClearDTC
            IN_VeLLSR_b_HVCurrent_Inv_VeLLSR_b_HVCurrent_Inv: accessed-variable=VeLLSR_b_HVCurrent_Inv.VeLLSR_b_HVCurrent_Inv
            IN_VeLLSR_b_Heat2PackVolt_Inv_VeLLSR_b_Heat2PackVolt_Inv: accessed-variable=VeLLSR_b_Heat2PackVolt_Inv.VeLLSR_b_Heat2PackVolt_Inv
            IN_VeLLSR_b_LinkN2PackVolt_Inv_VeLLSR_b_LinkN2PackVolt_Inv: accessed-variable=VeLLSR_b_LinkN2PackVolt_Inv.VeLLSR_b_LinkN2PackVolt_Inv
            IN_VeLLSR_b_LinkP2PackVolt_Inv_VeLLSR_b_LinkP2PackVolt_Inv: accessed-variable=VeLLSR_b_LinkP2PackVolt_Inv.VeLLSR_b_LinkP2PackVolt_Inv
            IN_VeLLSR_b_PackVoltage_Inv_VeLLSR_b_PackVoltage_Inv: accessed-variable=VeLLSR_b_PackVoltage_Inv.VeLLSR_b_PackVoltage_Inv
            IN_VeLLSR_k_CurSensorType_VeLLSR_k_CurSensorType: accessed-variable=VeLLSR_k_CurSensorType.VeLLSR_k_CurSensorType
        data-send-points:
          44 x access:
            OUT_VaCSCR_U_CellVoltageArray_out_VaCSCR_U_Ce_12acd3d420075e9e: accessed-variable=VaCSCR_U_CellVoltageArray_out.VaCSCR_U_CellVoltageArray_out
            OUT_VaCSCR_b_CellVoltageArrayFaulted_out_VaCS_df00bc1c29474f6c: accessed-variable=VaCSCR_b_CellVoltageArrayFaulted_out.VaCSCR_b_CellVoltageArrayFaulted_out
            OUT_VeCSCR_U_MaxCellVoltageMod_VeCSCR_U_MaxCellVoltageMod: accessed-variable=VeCSCR_U_MaxCellVoltageMod.VeCSCR_U_MaxCellVoltageMod
            OUT_VeCSCR_n_MaxCellVoltageIndex_VeCSCR_n_MaxCellVoltageIndex: accessed-variable=VeCSCR_n_MaxCellVoltageIndex.VeCSCR_n_MaxCellVoltageIndex
            OUT_VeCSCR_U_MinCellVoltageMod_VeCSCR_U_MinCellVoltageMod: accessed-variable=VeCSCR_U_MinCellVoltageMod.VeCSCR_U_MinCellVoltageMod
            OUT_VeCSCR_n_MinCellVoltageIndex_VeCSCR_n_MinCellVoltageIndex: accessed-variable=VeCSCR_n_MinCellVoltageIndex.VeCSCR_n_MinCellVoltageIndex
            OUT_VeCSCR_U_DeltaCellVoltage_VeCSCR_U_DeltaCellVoltage: accessed-variable=VeCSCR_U_DeltaCellVoltage.VeCSCR_U_DeltaCellVoltage
            OUT_VeCSCR_U_SumPackVoltageMod_VeCSCR_U_SumPackVoltageMod: accessed-variable=VeCSCR_U_SumPackVoltageMod.VeCSCR_U_SumPackVoltageMod
            OUT_VeCSCR_U_AvgCellVoltageMod_VeCSCR_U_AvgCellVoltageMod: accessed-variable=VeCSCR_U_AvgCellVoltageMod.VeCSCR_U_AvgCellVoltageMod
            OUT_VeCSCR_U_VoltageStandardDevMod_VeCSCR_U_V_00c0d53797ee8992: accessed-variable=VeCSCR_U_VoltageStandardDevMod.VeCSCR_U_VoltageStandardDevMod
            OUT_VeCSCR_U_PackVoltage_out_VeCSCR_U_PackVoltage_out: accessed-variable=VeCSCR_U_PackVoltage_out.VeCSCR_U_PackVoltage_out
            OUT_VaCSCR_U_StackArray_out_VaCSCR_U_StackArray_out: accessed-variable=VaCSCR_U_StackArray_out.VaCSCR_U_StackArray_out
            OUT_VaCSCR_b_StackArrayFaulted_out_VaCSCR_b_S_d57c0a3db1b586ac: accessed-variable=VaCSCR_b_StackArrayFaulted_out.VaCSCR_b_StackArrayFaulted_out
            OUT_VaCSCR_I_CellCurrentArray_out_VaCSCR_I_Ce_84a43db80022421e: accessed-variable=VaCSCR_I_CellCurrentArray_out.VaCSCR_I_CellCurrentArray_out
            OUT_VaCSCR_b_CellCurrentArrayFaulted_out_VaCS_7162b79e3902a426: accessed-variable=VaCSCR_b_CellCurrentArrayFaulted_out.VaCSCR_b_CellCurrentArrayFaulted_out
            OUT_VeCSCR_U_CellVoltage_VeCSCR_U_CellVoltage: accessed-variable=VeCSCR_U_CellVoltage.VeCSCR_U_CellVoltage
            OUT_VeCSCR_n_CellVoltSensorIndex_VeCSCR_n_CellVoltSensorIndex: accessed-variable=VeCSCR_n_CellVoltSensorIndex.VeCSCR_n_CellVoltSensorIndex
            OUT_VeCSCR_U_BattVoltForDB_VeCSCR_U_BattVoltForDB: accessed-variable=VeCSCR_U_BattVoltForDB.VeCSCR_U_BattVoltForDB
            OUT_VeCSCR_k_CellCircuit_flt_VeCSCR_k_CellCircuit_flt: accessed-variable=VeCSCR_k_CellCircuit_flt.VeCSCR_k_CellCircuit_flt
            OUT_VeCSCR_k_StackCircuit_flt_VeCSCR_k_StackCircuit_flt: accessed-variable=VeCSCR_k_StackCircuit_flt.VeCSCR_k_StackCircuit_flt
            OUT_VeCSCR_b_CellCurrentArray_flt_VeCSCR_b_Ce_8abb2419c4be8f8f: accessed-variable=VeCSCR_b_CellCurrentArray_flt.VeCSCR_b_CellCurrentArray_flt
            OUT_VeCSCR_U_SumStackVoltages_VeCSCR_U_SumStackVoltages: accessed-variable=VeCSCR_U_SumStackVoltages.VeCSCR_U_SumStackVoltages
            OUT_VeCSCR_b_CurrSensor_flt_VeCSCR_b_CurrSensor_flt: accessed-variable=VeCSCR_b_CurrSensor_flt.VeCSCR_b_CurrSensor_flt
            OUT_VeCSCR_U_LinkN2PackVolt_out_VeCSCR_U_LinkN2PackVolt_out: accessed-variable=VeCSCR_U_LinkN2PackVolt_out.VeCSCR_U_LinkN2PackVolt_out
            OUT_VeCSCR_b_PackVoltageFltd_VeCSCR_b_PackVoltageFltd: accessed-variable=VeCSCR_b_PackVoltageFltd.VeCSCR_b_PackVoltageFltd
            OUT_VeCSCR_I_HVCurrent_VeCSCR_I_HVCurrent: accessed-variable=VeCSCR_I_HVCurrent.VeCSCR_I_HVCurrent
            OUT_VeCSCR_b_HVCurrentFaulted_VeCSCR_b_HVCurrentFaulted: accessed-variable=VeCSCR_b_HVCurrentFaulted.VeCSCR_b_HVCurrentFaulted
            OUT_VeCSCR_k_CurSensorType_VeCSCR_k_CurSensorType: accessed-variable=VeCSCR_k_CurSensorType.VeCSCR_k_CurSensorType
            OUT_VeCSCR_b_CellUArrayReady_VeCSCR_b_CellUArrayReady: accessed-variable=VeCSCR_b_CellUArrayReady.VeCSCR_b_CellUArrayReady
            OUT_VeCSCR_k_CBCircuit_flt_VeCSCR_k_CBCircuit_flt: accessed-variable=VeCSCR_k_CBCircuit_flt.VeCSCR_k_CBCircuit_flt
            OUT_VeCSCR_b_CellVoltage_Inv_VeCSCR_b_CellVoltage_Inv: accessed-variable=VeCSCR_b_CellVoltage_Inv.VeCSCR_b_CellVoltage_Inv
            OUT_VeCSCR_U_Heat2PackVolt_out_VeCSCR_U_Heat2PackVolt_out: accessed-variable=VeCSCR_U_Heat2PackVolt_out.VeCSCR_U_Heat2PackVolt_out
            OUT_VeCSCR_U_LinkP2PackVolt_out_VeCSCR_U_LinkP2PackVolt_out: accessed-variable=VeCSCR_U_LinkP2PackVolt_out.VeCSCR_U_LinkP2PackVolt_out
            OUT_VeCSCR_n_MaxVoltIndexPack_VeCSCR_n_MaxVoltIndexPack: accessed-variable=VeCSCR_n_MaxVoltIndexPack.VeCSCR_n_MaxVoltIndexPack
            OUT_VeCSCR_n_MinVoltIndexPack_VeCSCR_n_MinVoltIndexPack: accessed-variable=VeCSCR_n_MinVoltIndexPack.VeCSCR_n_MinVoltIndexPack
            OUT_VeCSCR_U_LinkP2PackVolt_CAN_VeCSCR_U_LinkP2PackVolt_CAN: accessed-variable=VeCSCR_U_LinkP2PackVolt_CAN.VeCSCR_U_LinkP2PackVolt_CAN
            OUT_VeCSCR_U_LinkN2PackVolt_CAN_VeCSCR_U_LinkN2PackVolt_CAN: accessed-variable=VeCSCR_U_LinkN2PackVolt_CAN.VeCSCR_U_LinkN2PackVolt_CAN
            OUT_VeCSCR_U_Heat2PackVolt_CAN_VeCSCR_U_Heat2PackVolt_CAN: accessed-variable=VeCSCR_U_Heat2PackVolt_CAN.VeCSCR_U_Heat2PackVolt_CAN
            OUT_VeCSCR_k_PackVolt_flt_VeCSCR_k_PackVolt_flt: accessed-variable=VeCSCR_k_PackVolt_flt.VeCSCR_k_PackVolt_flt
            OUT_VeCSCR_k_LinkPVolt_flt_VeCSCR_k_LinkPVolt_flt: accessed-variable=VeCSCR_k_LinkPVolt_flt.VeCSCR_k_LinkPVolt_flt
            OUT_VeCSCR_k_LinkNVolt_flt_VeCSCR_k_LinkNVolt_flt: accessed-variable=VeCSCR_k_LinkNVolt_flt.VeCSCR_k_LinkNVolt_flt
            OUT_VeCSCR_k_HeatVolt_flt_VeCSCR_k_HeatVolt_flt: accessed-variable=VeCSCR_k_HeatVolt_flt.VeCSCR_k_HeatVolt_flt
            OUT_VeCSCR_I_PackShuntCurrent_VeCSCR_I_PackShuntCurrent: accessed-variable=VeCSCR_I_PackShuntCurrent.VeCSCR_I_PackShuntCurrent
            OUT_VeCSCR_b_PackShuntCurrentFaulted_VeCSCR_b_ef1ccd7c553f6753: accessed-variable=VeCSCR_b_PackShuntCurrentFaulted.VeCSCR_b_PackShuntCurrentFaulted
        109 x parameter access:
          CALPRM_CSCR_Rport_KaCSCR_I_OvrdCellCurrArrayVals: accessed-parameter=CSCR_Rport.KaCSCR_I_OvrdCellCurrArrayVals
          CALPRM_CSCR_Rport_KaCSCR_U_OvrdCellVoltArrayVals: accessed-parameter=CSCR_Rport.KaCSCR_U_OvrdCellVoltArrayVals
          CALPRM_CSCR_Rport_KaCSCR_U_OvrdStackVoltValue: accessed-parameter=CSCR_Rport.KaCSCR_U_OvrdStackVoltValue
          CALPRM_CSCR_Rport_KaCSCR_b_OvrdCellVoltArrayFaultedVals: accessed-parameter=CSCR_Rport.KaCSCR_b_OvrdCellVoltArrayFaultedVals
          CALPRM_CSCR_Rport_KaLLSR_b_CellCircuitFaulted_Val: accessed-parameter=CSCR_Rport.KaLLSR_b_CellCircuitFaulted_Val
          CALPRM_CSCR_Rport_KaLLSR_b_StackCircuitFaulted_Val: accessed-parameter=CSCR_Rport.KaLLSR_b_StackCircuitFaulted_Val
          CALPRM_CSCR_Rport_KeCSCR_Cnt_NumberofStacks: accessed-parameter=CSCR_Rport.KeCSCR_Cnt_NumberofStacks
          CALPRM_CSCR_Rport_KeCSCR_I_HVCurrent_En: accessed-parameter=CSCR_Rport.KeCSCR_I_HVCurrent_En
          CALPRM_CSCR_Rport_KeCSCR_I_HVCurrent_Val: accessed-parameter=CSCR_Rport.KeCSCR_I_HVCurrent_Val
          CALPRM_CSCR_Rport_KeCSCR_I_PackCurrDefaultVal: accessed-parameter=CSCR_Rport.KeCSCR_I_PackCurrDefaultVal
          CALPRM_CSCR_Rport_KeCSCR_I_ShuntCurrent_En: accessed-parameter=CSCR_Rport.KeCSCR_I_ShuntCurrent_En
          CALPRM_CSCR_Rport_KeCSCR_I_ShuntCurrent_Val: accessed-parameter=CSCR_Rport.KeCSCR_I_ShuntCurrent_Val
          CALPRM_CSCR_Rport_KeCSCR_U_BattVoltForDBOvrdVal: accessed-parameter=CSCR_Rport.KeCSCR_U_BattVoltForDBOvrdVal
          CALPRM_CSCR_Rport_KeCSCR_U_CellVoltArrayDefaultVals: accessed-parameter=CSCR_Rport.KeCSCR_U_CellVoltArrayDefaultVals
          CALPRM_CSCR_Rport_KeCSCR_U_CellVoltageArray_out_maxVal: accessed-parameter=CSCR_Rport.KeCSCR_U_CellVoltageArray_out_maxVal
          CALPRM_CSCR_Rport_KeCSCR_U_CellVoltageArray_out_minVal: accessed-parameter=CSCR_Rport.KeCSCR_U_CellVoltageArray_out_minVal
          CALPRM_CSCR_Rport_KeCSCR_U_CellVoltageOvrdVal: accessed-parameter=CSCR_Rport.KeCSCR_U_CellVoltageOvrdVal
          CALPRM_CSCR_Rport_KeCSCR_U_DeltaCellVoltage_Val: accessed-parameter=CSCR_Rport.KeCSCR_U_DeltaCellVoltage_Val
          CALPRM_CSCR_Rport_KeCSCR_U_Heat2PackVolt_En: accessed-parameter=CSCR_Rport.KeCSCR_U_Heat2PackVolt_En
          CALPRM_CSCR_Rport_KeCSCR_U_Heat2PackVolt_Val: accessed-parameter=CSCR_Rport.KeCSCR_U_Heat2PackVolt_Val
          CALPRM_CSCR_Rport_KeCSCR_U_Heat2PackVolt_maxVal: accessed-parameter=CSCR_Rport.KeCSCR_U_Heat2PackVolt_maxVal
          CALPRM_CSCR_Rport_KeCSCR_U_Heat2PackVolt_minVal: accessed-parameter=CSCR_Rport.KeCSCR_U_Heat2PackVolt_minVal
          CALPRM_CSCR_Rport_KeCSCR_U_Heat2PackVoltageDefaultVal: accessed-parameter=CSCR_Rport.KeCSCR_U_Heat2PackVoltageDefaultVal
          CALPRM_CSCR_Rport_KeCSCR_U_LinkNeg2PackVolt_En: accessed-parameter=CSCR_Rport.KeCSCR_U_LinkNeg2PackVolt_En
          CALPRM_CSCR_Rport_KeCSCR_U_LinkNeg2PackVolt_Val: accessed-parameter=CSCR_Rport.KeCSCR_U_LinkNeg2PackVolt_Val
          CALPRM_CSCR_Rport_KeCSCR_U_LinkNeg2PackVolt_maxVal: accessed-parameter=CSCR_Rport.KeCSCR_U_LinkNeg2PackVolt_maxVal
          CALPRM_CSCR_Rport_KeCSCR_U_LinkNeg2PackVolt_minVal: accessed-parameter=CSCR_Rport.KeCSCR_U_LinkNeg2PackVolt_minVal
          CALPRM_CSCR_Rport_KeCSCR_U_LinkNeg2PackVoltageDefaultVal: accessed-parameter=CSCR_Rport.KeCSCR_U_LinkNeg2PackVoltageDefaultVal
          CALPRM_CSCR_Rport_KeCSCR_U_LinkPos2PackVoltageDefaultVal: accessed-parameter=CSCR_Rport.KeCSCR_U_LinkPos2PackVoltageDefaultVal
          CALPRM_CSCR_Rport_KeCSCR_U_LinkPos2PackVoltage_out_maxVal: accessed-parameter=CSCR_Rport.KeCSCR_U_LinkPos2PackVoltage_out_maxVal
          CALPRM_CSCR_Rport_KeCSCR_U_LinkPos2PackVoltage_out_minVal: accessed-parameter=CSCR_Rport.KeCSCR_U_LinkPos2PackVoltage_out_minVal
          CALPRM_CSCR_Rport_KeCSCR_U_MaxCellVoltOvrdVal: accessed-parameter=CSCR_Rport.KeCSCR_U_MaxCellVoltOvrdVal
          CALPRM_CSCR_Rport_KeCSCR_U_MaxCellVoltageMod_maxVal: accessed-parameter=CSCR_Rport.KeCSCR_U_MaxCellVoltageMod_maxVal
          CALPRM_CSCR_Rport_KeCSCR_U_MaxCellVoltageMod_minVal: accessed-parameter=CSCR_Rport.KeCSCR_U_MaxCellVoltageMod_minVal
          CALPRM_CSCR_Rport_KeCSCR_U_MinCellVoltOvrdVal: accessed-parameter=CSCR_Rport.KeCSCR_U_MinCellVoltOvrdVal
          CALPRM_CSCR_Rport_KeCSCR_U_MinCellVoltageMod_maxVal: accessed-parameter=CSCR_Rport.KeCSCR_U_MinCellVoltageMod_maxVal
          CALPRM_CSCR_Rport_KeCSCR_U_MinCellVoltageMod_minVal: accessed-parameter=CSCR_Rport.KeCSCR_U_MinCellVoltageMod_minVal
          CALPRM_CSCR_Rport_KeCSCR_U_OvrdAvgCellVoltVal: accessed-parameter=CSCR_Rport.KeCSCR_U_OvrdAvgCellVoltVal
          CALPRM_CSCR_Rport_KeCSCR_U_OvrdLinkVoltValue: accessed-parameter=CSCR_Rport.KeCSCR_U_OvrdLinkVoltValue
          CALPRM_CSCR_Rport_KeCSCR_U_OvrdPackVoltValue: accessed-parameter=CSCR_Rport.KeCSCR_U_OvrdPackVoltValue
          CALPRM_CSCR_Rport_KeCSCR_U_PackVoltageDefaultVal: accessed-parameter=CSCR_Rport.KeCSCR_U_PackVoltageDefaultVal
          CALPRM_CSCR_Rport_KeCSCR_U_PackVoltage_out_maxVal: accessed-parameter=CSCR_Rport.KeCSCR_U_PackVoltage_out_maxVal
          CALPRM_CSCR_Rport_KeCSCR_U_PackVoltage_out_minVal: accessed-parameter=CSCR_Rport.KeCSCR_U_PackVoltage_out_minVal
          CALPRM_CSCR_Rport_KeCSCR_U_SumPackVoltOvrdVal: accessed-parameter=CSCR_Rport.KeCSCR_U_SumPackVoltOvrdVal
          CALPRM_CSCR_Rport_KeCSCR_U_SumPackVoltageMod_maxVal: accessed-parameter=CSCR_Rport.KeCSCR_U_SumPackVoltageMod_maxVal
          CALPRM_CSCR_Rport_KeCSCR_U_SumPackVoltageMod_minVal: accessed-parameter=CSCR_Rport.KeCSCR_U_SumPackVoltageMod_minVal
          CALPRM_CSCR_Rport_KeCSCR_U_ThrshldDiffVoltSumCellPack: accessed-parameter=CSCR_Rport.KeCSCR_U_ThrshldDiffVoltSumCellPack
          CALPRM_CSCR_Rport_KeCSCR_b_BattVoltForDBOvrd: accessed-parameter=CSCR_Rport.KeCSCR_b_BattVoltForDBOvrd
          CALPRM_CSCR_Rport_KeCSCR_b_CBCircuit_flt_En: accessed-parameter=CSCR_Rport.KeCSCR_b_CBCircuit_flt_En
          CALPRM_CSCR_Rport_KeCSCR_b_CellCircuit_flt_En: accessed-parameter=CSCR_Rport.KeCSCR_b_CellCircuit_flt_En
          CALPRM_CSCR_Rport_KeCSCR_b_CellCurrentArrayFltEnable: accessed-parameter=CSCR_Rport.KeCSCR_b_CellCurrentArrayFltEnable
          CALPRM_CSCR_Rport_KeCSCR_b_CellUArrayReady_En: accessed-parameter=CSCR_Rport.KeCSCR_b_CellUArrayReady_En
          CALPRM_CSCR_Rport_KeCSCR_b_CellUArrayReady_Val: accessed-parameter=CSCR_Rport.KeCSCR_b_CellUArrayReady_Val
          CALPRM_CSCR_Rport_KeCSCR_b_CellVoltSensorIndexOvrd: accessed-parameter=CSCR_Rport.KeCSCR_b_CellVoltSensorIndexOvrd
          CALPRM_CSCR_Rport_KeCSCR_b_CellVoltageOvrd: accessed-parameter=CSCR_Rport.KeCSCR_b_CellVoltageOvrd
          CALPRM_CSCR_Rport_KeCSCR_b_CellVoltage_Inv_En: accessed-parameter=CSCR_Rport.KeCSCR_b_CellVoltage_Inv_En
          CALPRM_CSCR_Rport_KeCSCR_b_CellVoltage_Inv_Val: accessed-parameter=CSCR_Rport.KeCSCR_b_CellVoltage_Inv_Val
          CALPRM_CSCR_Rport_KeCSCR_b_CurrSensor_flt_En: accessed-parameter=CSCR_Rport.KeCSCR_b_CurrSensor_flt_En
          CALPRM_CSCR_Rport_KeCSCR_b_CurrSensor_flt_Val: accessed-parameter=CSCR_Rport.KeCSCR_b_CurrSensor_flt_Val
          CALPRM_CSCR_Rport_KeCSCR_b_DeltaCellVoltage_En: accessed-parameter=CSCR_Rport.KeCSCR_b_DeltaCellVoltage_En
          CALPRM_CSCR_Rport_KeCSCR_b_FaultValFilterEn: accessed-parameter=CSCR_Rport.KeCSCR_b_FaultValFilterEn
          CALPRM_CSCR_Rport_KeCSCR_b_HVCurrentFaulted_En: accessed-parameter=CSCR_Rport.KeCSCR_b_HVCurrentFaulted_En
          CALPRM_CSCR_Rport_KeCSCR_b_HVCurrentFaulted_Val: accessed-parameter=CSCR_Rport.KeCSCR_b_HVCurrentFaulted_Val
          CALPRM_CSCR_Rport_KeCSCR_b_Heat2PackVoltFltd_En: accessed-parameter=CSCR_Rport.KeCSCR_b_Heat2PackVoltFltd_En
          CALPRM_CSCR_Rport_KeCSCR_b_Heat2PackVoltFltd_Val: accessed-parameter=CSCR_Rport.KeCSCR_b_Heat2PackVoltFltd_Val
          CALPRM_CSCR_Rport_KeCSCR_b_LinkNeg2PackVoltFltd_En: accessed-parameter=CSCR_Rport.KeCSCR_b_LinkNeg2PackVoltFltd_En
          CALPRM_CSCR_Rport_KeCSCR_b_LinkNeg2PackVoltFltd_Val: accessed-parameter=CSCR_Rport.KeCSCR_b_LinkNeg2PackVoltFltd_Val
          CALPRM_CSCR_Rport_KeCSCR_b_LinkPos2PackVoltageFltd_En: accessed-parameter=CSCR_Rport.KeCSCR_b_LinkPos2PackVoltageFltd_En
          CALPRM_CSCR_Rport_KeCSCR_b_LinkPos2PackVoltageFltd_Val: accessed-parameter=CSCR_Rport.KeCSCR_b_LinkPos2PackVoltageFltd_Val
          CALPRM_CSCR_Rport_KeCSCR_b_MaxVoltIndexPackOvrd: accessed-parameter=CSCR_Rport.KeCSCR_b_MaxVoltIndexPackOvrd
          CALPRM_CSCR_Rport_KeCSCR_b_MinVoltIndexPackOvrd: accessed-parameter=CSCR_Rport.KeCSCR_b_MinVoltIndexPackOvrd
          CALPRM_CSCR_Rport_KeCSCR_b_OvrdAvgCellVolt: accessed-parameter=CSCR_Rport.KeCSCR_b_OvrdAvgCellVolt
          CALPRM_CSCR_Rport_KeCSCR_b_OvrdCellVoltArrayFaulted: accessed-parameter=CSCR_Rport.KeCSCR_b_OvrdCellVoltArrayFaulted
          CALPRM_CSCR_Rport_KeCSCR_b_OvrdCurrentArray: accessed-parameter=CSCR_Rport.KeCSCR_b_OvrdCurrentArray
          CALPRM_CSCR_Rport_KeCSCR_b_OvrdCurrentArrayFltArray: accessed-parameter=CSCR_Rport.KeCSCR_b_OvrdCurrentArrayFltArray
          CALPRM_CSCR_Rport_KeCSCR_b_OvrdCurrentArrayFltArrayVals: accessed-parameter=CSCR_Rport.KeCSCR_b_OvrdCurrentArrayFltArrayVals
          CALPRM_CSCR_Rport_KeCSCR_b_OvrdLinkVolt: accessed-parameter=CSCR_Rport.KeCSCR_b_OvrdLinkVolt
          CALPRM_CSCR_Rport_KeCSCR_b_OvrdMaxCellVolt: accessed-parameter=CSCR_Rport.KeCSCR_b_OvrdMaxCellVolt
          CALPRM_CSCR_Rport_KeCSCR_b_OvrdMaxCellVoltIndex: accessed-parameter=CSCR_Rport.KeCSCR_b_OvrdMaxCellVoltIndex
          CALPRM_CSCR_Rport_KeCSCR_b_OvrdMinCellVolt: accessed-parameter=CSCR_Rport.KeCSCR_b_OvrdMinCellVolt
          CALPRM_CSCR_Rport_KeCSCR_b_OvrdMinCellVoltIndex: accessed-parameter=CSCR_Rport.KeCSCR_b_OvrdMinCellVoltIndex
          CALPRM_CSCR_Rport_KeCSCR_b_OvrdPackVolt: accessed-parameter=CSCR_Rport.KeCSCR_b_OvrdPackVolt
          CALPRM_CSCR_Rport_KeCSCR_b_OvrdStackVolt: accessed-parameter=CSCR_Rport.KeCSCR_b_OvrdStackVolt
          CALPRM_CSCR_Rport_KeCSCR_b_OvrdSumPackVolt: accessed-parameter=CSCR_Rport.KeCSCR_b_OvrdSumPackVolt
          CALPRM_CSCR_Rport_KeCSCR_b_OvrdVoltArray: accessed-parameter=CSCR_Rport.KeCSCR_b_OvrdVoltArray
          CALPRM_CSCR_Rport_KeCSCR_b_OvrdVoltStandardDev: accessed-parameter=CSCR_Rport.KeCSCR_b_OvrdVoltStandardDev
          CALPRM_CSCR_Rport_KeCSCR_b_PackVoltageFltd_En: accessed-parameter=CSCR_Rport.KeCSCR_b_PackVoltageFltd_En
          CALPRM_CSCR_Rport_KeCSCR_b_PackVoltageFltd_Val: accessed-parameter=CSCR_Rport.KeCSCR_b_PackVoltageFltd_Val
          CALPRM_CSCR_Rport_KeCSCR_b_ShuntCurrentFaulted_En: accessed-parameter=CSCR_Rport.KeCSCR_b_ShuntCurrentFaulted_En
          CALPRM_CSCR_Rport_KeCSCR_b_ShuntCurrentFaulted_Val: accessed-parameter=CSCR_Rport.KeCSCR_b_ShuntCurrentFaulted_Val
          CALPRM_CSCR_Rport_KeCSCR_b_StackCircuit_flt_En: accessed-parameter=CSCR_Rport.KeCSCR_b_StackCircuit_flt_En
          CALPRM_CSCR_Rport_KeCSCR_k_CBCircuit_flt_Val: accessed-parameter=CSCR_Rport.KeCSCR_k_CBCircuit_flt_Val
          CALPRM_CSCR_Rport_KeCSCR_k_CellCircuit_flt_Val: accessed-parameter=CSCR_Rport.KeCSCR_k_CellCircuit_flt_Val
          CALPRM_CSCR_Rport_KeCSCR_k_CurSensorType_En: accessed-parameter=CSCR_Rport.KeCSCR_k_CurSensorType_En
          CALPRM_CSCR_Rport_KeCSCR_k_CurSensorType_Val: accessed-parameter=CSCR_Rport.KeCSCR_k_CurSensorType_Val
          CALPRM_CSCR_Rport_KeCSCR_k_StackCircuit_flt_Val: accessed-parameter=CSCR_Rport.KeCSCR_k_StackCircuit_flt_Val
          CALPRM_CSCR_Rport_KeCSCR_n_CellVoltSensorIndexOvrdVal: accessed-parameter=CSCR_Rport.KeCSCR_n_CellVoltSensorIndexOvrdVal
          CALPRM_CSCR_Rport_KeCSCR_n_MaxCellVoltIndexOvrdVal: accessed-parameter=CSCR_Rport.KeCSCR_n_MaxCellVoltIndexOvrdVal
          CALPRM_CSCR_Rport_KeCSCR_n_MaxVoltIndexPackOvrdVal: accessed-parameter=CSCR_Rport.KeCSCR_n_MaxVoltIndexPackOvrdVal
          CALPRM_CSCR_Rport_KeCSCR_n_MinCellVoltIndexOvrdVal: accessed-parameter=CSCR_Rport.KeCSCR_n_MinCellVoltIndexOvrdVal
          CALPRM_CSCR_Rport_KeCSCR_n_MinVoltIndexPackOvrdVal: accessed-parameter=CSCR_Rport.KeCSCR_n_MinVoltIndexPackOvrdVal
          CALPRM_CSCR_Rport_KeCSCR_n_OvrdVoltStandardDevVal: accessed-parameter=CSCR_Rport.KeCSCR_n_OvrdVoltStandardDevVal
          CALPRM_CSCR_Rport_KeCSCR_t_CBCircuitFaultMaturation: accessed-parameter=CSCR_Rport.KeCSCR_t_CBCircuitFaultMaturation
          CALPRM_CSCR_Rport_KeCSCR_t_FastSampleRate: accessed-parameter=CSCR_Rport.KeCSCR_t_FastSampleRate
          CALPRM_CSCR_Rport_KeCSCR_t_Maxinitwaittime: accessed-parameter=CSCR_Rport.KeCSCR_t_Maxinitwaittime
          CALPRM_CSCR_GCFR_Rport_KeGCFR_Cnt_NumberOfCSC: accessed-parameter=CSCR_GCFR_Rport.KeGCFR_Cnt_NumberOfCSC
          CALPRM_CSCR_GCFR_Rport_KeGCFR_Cnt_NumberofCells: accessed-parameter=CSCR_GCFR_Rport.KeGCFR_Cnt_NumberofCells
          CALPRM_CSCR_Rport_KeLLSR_b_CellCircuitFaulted_En: accessed-parameter=CSCR_Rport.KeLLSR_b_CellCircuitFaulted_En
          CALPRM_CSCR_Rport_KeLLSR_b_StackCircuitFaulted_En: accessed-parameter=CSCR_Rport.KeLLSR_b_StackCircuitFaulted_En
package /CalibrationComponents
  parameter sw component type CSCR: data-type-mapping=[CSCR_CodeDataTypeMappingsSet, WorkingDataTypeMappingsSet]
    provide port CSCR_Pport: provided-interface=CSCR_if
      provided-com-specs:
        init-value=CSCR_Pport_KaCSCR_I_OvrdCellCurrArrayVals:[1, 1], parameter=KaCSCR_I_OvrdCellCurrArrayVals
        init-value=CSCR_Pport_KaCSCR_T_OvrdCellTempArrayVals:16 x 1, parameter=KaCSCR_T_OvrdCellTempArrayVals
        init-value=CSCR_Pport_KaCSCR_U_OvrdCellVoltArrayVals:96 x 0, parameter=KaCSCR_U_OvrdCellVoltArrayVals
        init-value=CSCR_Pport_KaCSCR_U_OvrdStackVoltValue:8 x 0, parameter=KaCSCR_U_OvrdStackVoltValue
        init-value=CSCR_Pport_KaCSCR_dT_CellTempRate_out_Val:16 x 0, parameter=KaCSCR_dT_CellTempRate_out_Val
        init-value=0, parameter=KeCSCR_I_HVCurrent_Val
        init-value=0, parameter=KeCSCR_I_PackCurrDefaultVal
        init-value=0, parameter=KeCSCR_I_ShuntCurrent_Val
        init-value=0, parameter=KeCSCR_T_AvePCBTemp_Val
        init-value=130, parameter=KeCSCR_T_AvgCellTempMod_maxVal
        init-value=-45, parameter=KeCSCR_T_AvgCellTempMod_minVal
        init-value=130, parameter=KeCSCR_T_CellTempArray_out_maxVal
        init-value=-45, parameter=KeCSCR_T_CellTempArray_out_minVal
        init-value=0, parameter=KeCSCR_T_DeltaCellTemp_Val
        init-value=175, parameter=KeCSCR_T_DeltaCellTemp_maxVal
        init-value=0, parameter=KeCSCR_T_DeltaCellTemp_minVal
        init-value=130, parameter=KeCSCR_T_MaxCellTempMod_maxVal
        init-value=-45, parameter=KeCSCR_T_MaxCellTempMod_minVal
        init-value=0, parameter=KeCSCR_T_MaxCellTempOvrdVal
        init-value=0, parameter=KeCSCR_T_MaxPCBTemp_Val
        init-value=0, parameter=KeCSCR_T_MaxPackTempOvrdVal
        init-value=130, parameter=KeCSCR_T_MaxPackTemp_maxVal
        init-value=-45, parameter=KeCSCR_T_MaxPackTemp_minVal
        init-value=0, parameter=KeCSCR_T_MaxSenorTempOvrdVal
        init-value=42, parameter=KeCSCR_T_MaxTempFault
        init-value=130, parameter=KeCSCR_T_MinCellTempMod_maxVal
        init-value=-45, parameter=KeCSCR_T_MinCellTempMod_minVal
        init-value=0, parameter=KeCSCR_T_MinCellTempOvrdVal
        init-value=0, parameter=KeCSCR_T_MinPCBTemp_Val
        init-value=0, parameter=KeCSCR_T_MinPackTempOvrdVal
        init-value=130, parameter=KeCSCR_T_MinPackTemp_maxVal
        init-value=-45, parameter=KeCSCR_T_MinPackTemp_minVal
        init-value=0, parameter=KeCSCR_T_MinSenorTempOvrdVal
        init-value=-5, parameter=KeCSCR_T_MinTempFault
        init-value=0, parameter=KeCSCR_T_ModuleTemperatureOvrdVal
        init-value=0, parameter=KeCSCR_T_OvrdAvgCellTempVal
        init-value=100, parameter=KeCSCR_T_PCBTempDeftVal
        init-value=100, parameter=KeCSCR_T_WaterTempDeftVal
        init-value=0, parameter=KeCSCR_U_BattVoltForDBOvrdVal
        init-value=3.200000047683716, parameter=KeCSCR_U_CellVoltArrayDefaultVals
        init-value=5, parameter=KeCSCR_U_CellVoltageArray_out_maxVal
        init-value=0, parameter=KeCSCR_U_CellVoltageArray_out_minVal
        init-value=0, parameter=KeCSCR_U_CellVoltageOvrdVal
        init-value=0, parameter=KeCSCR_U_DeltaCellVoltage_Val
        init-value=0, parameter=KeCSCR_U_Heat2PackVolt_Val
        init-value=480, parameter=KeCSCR_U_Heat2PackVolt_maxVal
        init-value=0, parameter=KeCSCR_U_Heat2PackVolt_minVal
        init-value=0, parameter=KeCSCR_U_Heat2PackVoltageDefaultVal
        init-value=0, parameter=KeCSCR_U_LinkNeg2PackVolt_Val
        init-value=480, parameter=KeCSCR_U_LinkNeg2PackVolt_maxVal
        init-value=0, parameter=KeCSCR_U_LinkNeg2PackVolt_minVal
        init-value=0, parameter=KeCSCR_U_LinkNeg2PackVoltageDefaultVal
        init-value=0, parameter=KeCSCR_U_LinkPos2PackVoltageDefaultVal
        init-value=480, parameter=KeCSCR_U_LinkPos2PackVoltage_out_maxVal
        init-value=0, parameter=KeCSCR_U_LinkPos2PackVoltage_out_minVal
        init-value=0, parameter=KeCSCR_U_MaxCellVoltOvrdVal
        init-value=5, parameter=KeCSCR_U_MaxCellVoltageMod_maxVal
        init-value=0, parameter=KeCSCR_U_MaxCellVoltageMod_minVal
        init-value=0, parameter=KeCSCR_U_MinCellVoltOvrdVal
        init-value=5, parameter=KeCSCR_U_MinCellVoltageMod_maxVal
        init-value=0, parameter=KeCSCR_U_MinCellVoltageMod_minVal
        init-value=0, parameter=KeCSCR_U_OvrdAvgCellVoltVal
        init-value=0, parameter=KeCSCR_U_OvrdLinkVoltValue
        init-value=0, parameter=KeCSCR_U_OvrdPackVoltValue
        init-value=25, parameter=KeCSCR_U_PackTempDefaultVal
        init-value=288, parameter=KeCSCR_U_PackVoltageDefaultVal
        init-value=480, parameter=KeCSCR_U_PackVoltage_out_maxVal
        init-value=0, parameter=KeCSCR_U_PackVoltage_out_minVal
        init-value=0, parameter=KeCSCR_U_SumPackVoltOvrdVal
        init-value=480, parameter=KeCSCR_U_SumPackVoltageMod_maxVal
        init-value=0, parameter=KeCSCR_U_SumPackVoltageMod_minVal
        init-value=20, parameter=KeCSCR_U_ThrshldDiffVoltSumCellPack
        init-value=0, parameter=KeCSCR_n_OvrdVoltStandardDevVal
        init-value=0.00995016098022461, parameter=KeCSCR_r_TempLPFGain
        init-value=3.200000047683716, parameter=KeCSCR_t_CBCircuitFaultMaturation
        init-value=1, parameter=KeCSCR_t_CellTempRateTimeConstant
        init-value=0.009999999776482582, parameter=KeCSCR_t_FastSampleRate
        init-value=0.5, parameter=KeCSCR_t_Maxinitwaittime
        init-value=0.10000000149011612, parameter=KeCSCR_t_SlowSampleRate
        init-value=19.200000762939453, parameter=KeCSCR_t_TempCircuitFaultDeMaturation
        init-value=19.200000762939453, parameter=KeCSCR_t_TempCircuitFaultMaturation
        init-value=0.10000000149011612, parameter=KeCSCR_t_TempFncCall
        init-value=15, parameter=KeCSCR_t_TempLPFWarmupTime
        init-value=1, parameter=KeCSCR_Cnt_DeltaCellTempFltDbnc
        init-value=CSCR_Pport_KaCSCR_b_OvrdCellTempFltArrayVals:16 x 0, parameter=KaCSCR_b_OvrdCellTempFltArrayVals
        init-value=CSCR_Pport_KaCSCR_b_OvrdCellVoltArrayFaultedVals:96 x 0, parameter=KaCSCR_b_OvrdCellVoltArrayFaultedVals
        init-value=0, parameter=KaCSCR_b_WaterTemp_Inv_En
        init-value=CSCR_Pport_KaCSCR_b_WaterTemp_Inv_Val:[0, 0], parameter=KaCSCR_b_WaterTemp_Inv_Val
        init-value=CSCR_Pport_KaLLSR_b_CellCircuitFaulted_Val:96 x 0, parameter=KaLLSR_b_CellCircuitFaulted_Val
        init-value=CSCR_Pport_KaLLSR_b_StackCircuitFaulted_Val:8 x 0, parameter=KaLLSR_b_StackCircuitFaulted_Val
        init-value=CSCR_Pport_KaLLSR_b_TempCircuitFaulted_Val:16 x 0, parameter=KaLLSR_b_TempCircuitFaulted_Val
        init-value=0, parameter=KaLLSR_b_WaterTempCircuitFaulted_Val
        init-value=0, parameter=KeCSCR_I_HVCurrent_En
        init-value=0, parameter=KeCSCR_I_ShuntCurrent_En
        init-value=0, parameter=KeCSCR_U_Heat2PackVolt_En
        init-value=0, parameter=KeCSCR_U_LinkNeg2PackVolt_En
        init-value=0, parameter=KeCSCR_b_AvePCBTemp_En
        init-value=0, parameter=KeCSCR_b_BattVoltForDBOvrd
        init-value=0, parameter=KeCSCR_b_BatteryTempMismatchOvrd
        init-value=0, parameter=KeCSCR_b_BatteryTempMismatchOvrdVal
        init-value=0, parameter=KeCSCR_b_BatteryUniformityOvrd
        init-value=0, parameter=KeCSCR_b_BatteryUniformityOvrdVal
        init-value=0, parameter=KeCSCR_b_CBCircuit_flt_En
        init-value=0, parameter=KeCSCR_b_CellCircuit_flt_En
        init-value=1, parameter=KeCSCR_b_CellCurrentArrayFltEnable
        init-value=0, parameter=KeCSCR_b_CellTempLPFEnable
        init-value=0, parameter=KeCSCR_b_CellTempRate_out_En
        init-value=0, parameter=KeCSCR_b_CellTemp_Inv_En
        init-value=0, parameter=KeCSCR_b_CellTemp_Inv_Val
        init-value=0, parameter=KeCSCR_b_CellUArrayReady_En
        init-value=0, parameter=KeCSCR_b_CellUArrayReady_Val
        init-value=0, parameter=KeCSCR_b_CellVoltSensorIndexOvrd
        init-value=0, parameter=KeCSCR_b_CellVoltageOvrd
        init-value=0, parameter=KeCSCR_b_CellVoltage_Inv_En
        init-value=0, parameter=KeCSCR_b_CellVoltage_Inv_Val
        init-value=0, parameter=KeCSCR_b_CurrSensor_flt_En
        init-value=0, parameter=KeCSCR_b_CurrSensor_flt_Val
        init-value=0, parameter=KeCSCR_b_CurrentSensorFltOvrd
        init-value=0, parameter=KeCSCR_b_CurrentSensorFltOvrdVal
        init-value=0, parameter=KeCSCR_b_DeltaCellTempFltOvrd
        init-value=0, parameter=KeCSCR_b_DeltaCellTempFltOvrdVal
        init-value=0, parameter=KeCSCR_b_DeltaCellTemp_En
        init-value=0, parameter=KeCSCR_b_DeltaCellVoltage_En
        init-value=1, parameter=KeCSCR_b_FaultValFilterEn
        init-value=0, parameter=KeCSCR_b_HVCurrentFaulted_En
        init-value=0, parameter=KeCSCR_b_HVCurrentFaulted_Val
        init-value=0, parameter=KeCSCR_b_Heat2PackVoltFltd_En
        init-value=0, parameter=KeCSCR_b_Heat2PackVoltFltd_Val
        init-value=0, parameter=KeCSCR_b_LinkNeg2PackVoltFltd_En
        init-value=0, parameter=KeCSCR_b_LinkNeg2PackVoltFltd_Val
        init-value=0, parameter=KeCSCR_b_LinkPos2PackVoltageFltd_En
        init-value=0, parameter=KeCSCR_b_LinkPos2PackVoltageFltd_Val
        init-value=0, parameter=KeCSCR_b_MaxCellTempIndexOvrd
        init-value=0, parameter=KeCSCR_b_MaxPCBTempIndex_En
        init-value=0, parameter=KeCSCR_b_MaxPCBTemp_En
        init-value=0, parameter=KeCSCR_b_MaxPackTempOvrd
        init-value=0, parameter=KeCSCR_b_MaxSenorTempIndexOvrd
        init-value=0, parameter=KeCSCR_b_MaxSenorTempOvrd
        init-value=0, parameter=KeCSCR_b_MaxTempIndexPackOvrd
        init-value=0, parameter=KeCSCR_b_MaxVoltIndexPackOvrd
        init-value=0, parameter=KeCSCR_b_MinCellTempIndexOvrd
        init-value=0, parameter=KeCSCR_b_MinPCBTempIndex_En
        init-value=0, parameter=KeCSCR_b_MinPCBTemp_En
        init-value=0, parameter=KeCSCR_b_MinPackTempOvrd
        init-value=0, parameter=KeCSCR_b_MinSenorTempIndexOvrd
        init-value=0, parameter=KeCSCR_b_MinSenorTempOvrd
        init-value=0, parameter=KeCSCR_b_MinTempIndexPackOvrd
        init-value=0, parameter=KeCSCR_b_MinVoltIndexPackOvrd
        init-value=0, parameter=KeCSCR_b_ModuleTemperatureOvrd
        init-value=0, parameter=KeCSCR_b_OvrdAvgCellTemp
        init-value=0, parameter=KeCSCR_b_OvrdAvgCellVolt
        init-value=0, parameter=KeCSCR_b_OvrdCellVoltArrayFaulted
        init-value=0, parameter=KeCSCR_b_OvrdCurrentArray
        init-value=0, parameter=KeCSCR_b_OvrdCurrentArrayFltArray
        init-value=CSCR_Pport_KeCSCR_b_OvrdCurrentArrayFltArrayVals:[0, 0], parameter=KeCSCR_b_OvrdCurrentArrayFltArrayVals
        init-value=0, parameter=KeCSCR_b_OvrdLinkVolt
        init-value=0, parameter=KeCSCR_b_OvrdMaxCellTemp
        init-value=0, parameter=KeCSCR_b_OvrdMaxCellVolt
        init-value=0, parameter=KeCSCR_b_OvrdMaxCellVoltIndex
        init-value=0, parameter=KeCSCR_b_OvrdMinCellTemp
        init-value=0, parameter=KeCSCR_b_OvrdMinCellVolt
        init-value=0, parameter=KeCSCR_b_OvrdMinCellVoltIndex
        init-value=0, parameter=KeCSCR_b_OvrdPackVolt
        init-value=0, parameter=KeCSCR_b_OvrdStackVolt
        init-value=0, parameter=KeCSCR_b_OvrdSumPackVolt
        init-value=0, parameter=KeCSCR_b_OvrdTempArray
        init-value=0, parameter=KeCSCR_b_OvrdTempFltArray
        init-value=0, parameter=KeCSCR_b_OvrdVoltArray
        init-value=0, parameter=KeCSCR_b_OvrdVoltStandardDev
        init-value=0, parameter=KeCSCR_b_PCBTempLPFEnable
        init-value=0, parameter=KeCSCR_b_PCBTemp_Inv_En
        init-value=0, parameter=KeCSCR_b_PCBTemp_Inv_Val
        init-value=0, parameter=KeCSCR_b_PackVoltageFltd_En
        init-value=0, parameter=KeCSCR_b_PackVoltageFltd_Val
        init-value=0, parameter=KeCSCR_b_SafetyConnectStatus_En
        init-value=1, parameter=KeCSCR_b_SafetyConnectStatus_Val
        init-value=0, parameter=KeCSCR_b_ShuntCurrentFaulted_En
        init-value=0, parameter=KeCSCR_b_ShuntCurrentFaulted_Val
        init-value=0, parameter=KeCSCR_b_StackCircuit_flt_En
        init-value=0, parameter=KeCSCR_b_SysParamMismatchOvrd
        init-value=0, parameter=KeCSCR_b_SysParamMismatchOvrdVal
        init-value=0, parameter=KeCSCR_b_TempArray_flt_CAN_En
        init-value=0, parameter=KeCSCR_b_TempArray_flt_En
        init-value=0, parameter=KeCSCR_b_WaterTempLPFEnable
        init-value=0, parameter=KeCSCR_k_CurSensorType_En
        init-value=0, parameter=KeLLSR_b_CellCircuitFaulted_En
        init-value=0, parameter=KeLLSR_b_StackCircuitFaulted_En
        init-value=0, parameter=KeLLSR_b_TempCircuitFaulted_En
        init-value=0, parameter=KeLLSR_b_WaterTempCircuitFaulted_En
        init-value=11, parameter=KeCSCR_Cnt_NumPcbTempSens
        init-value=8, parameter=KeCSCR_Cnt_NumberofStacks
        init-value=1, parameter=KeCSCR_Cnt_ThermistorCountSingle
        init-value=0, parameter=KeCSCR_T_MaxSenorTempIndexOvrdVal
        init-value=0, parameter=KeCSCR_T_MinSenorTempIndexOvrdVal
        init-value=0, parameter=KeCSCR_k_CBCircuit_flt_Val
        init-value=0, parameter=KeCSCR_k_CellCircuit_flt_Val
        init-value=0, parameter=KeCSCR_k_CurSensorType_Val
        init-value=0, parameter=KeCSCR_k_StackCircuit_flt_Val
        init-value=0, parameter=KeCSCR_k_TempArray_flt_CAN_Val
        init-value=0, parameter=KeCSCR_k_TempArray_flt_Val
        init-value=0, parameter=KeCSCR_n_CellVoltSensorIndexOvrdVal
        init-value=0, parameter=KeCSCR_n_MaxCellTempIndexOvrdVal
        init-value=0, parameter=KeCSCR_n_MaxCellVoltIndexOvrdVal
        init-value=0, parameter=KeCSCR_n_MaxPCBTempIndex_Val
        init-value=0, parameter=KeCSCR_n_MaxTempIndexPackOvrdVal
        init-value=0, parameter=KeCSCR_n_MaxVoltIndexPackOvrdVal
        init-value=0, parameter=KeCSCR_n_MinCellTempIndexOvrdVal
        init-value=0, parameter=KeCSCR_n_MinCellVoltIndexOvrdVal
        init-value=0, parameter=KeCSCR_n_MinPCBTempIndex_Val
        init-value=0, parameter=KeCSCR_n_MinTempIndexPackOvrdVal
        init-value=0, parameter=KeCSCR_n_MinVoltIndexPackOvrdVal
